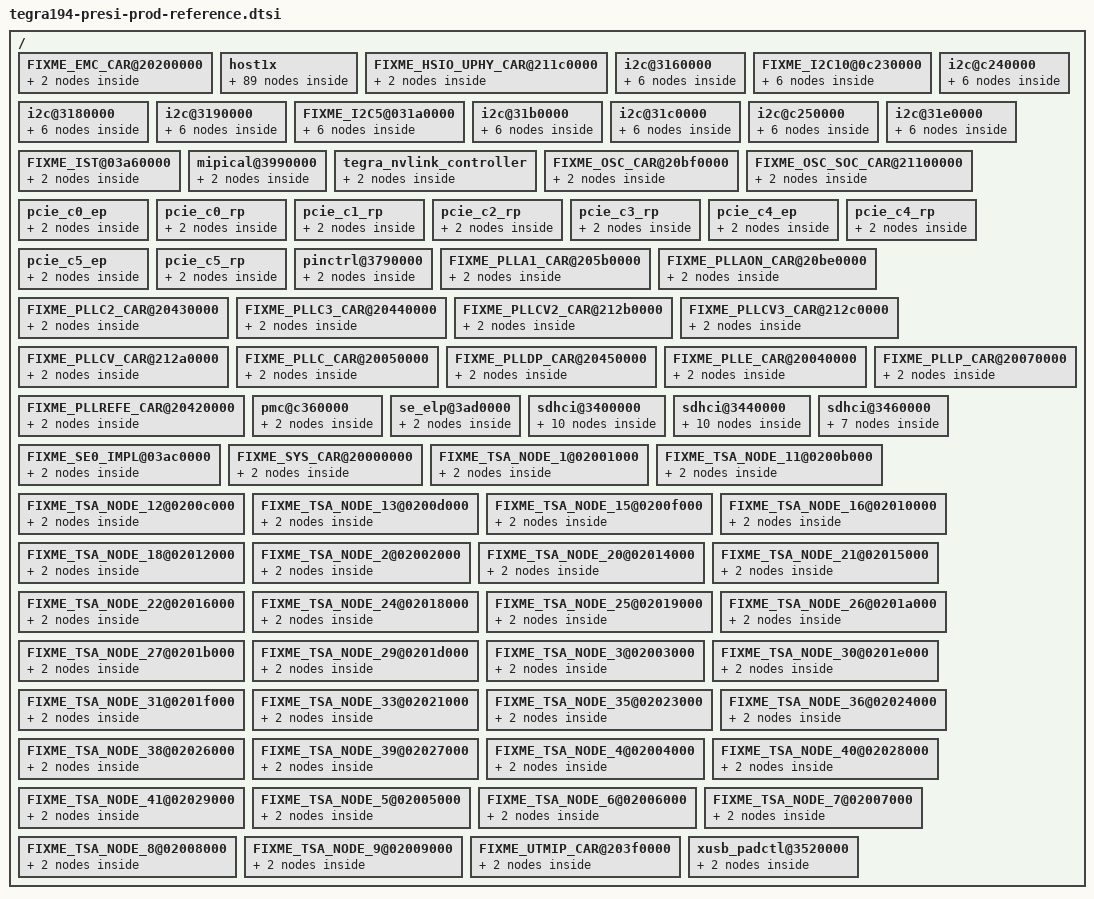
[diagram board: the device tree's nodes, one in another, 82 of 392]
/*
 * Copyright (c) 2017, NVIDIA CORPORATION.  All rights reserved.
 *
 * This program is free software; you can redistribute it and/or modify
 * it under the terms of the GNU General Public License as published by
 * the Free Software Foundation; version 2 of the License.
 *
 * This program is distributed in the hope that it will be useful, but WITHOUT
 * ANY WARRANTY; without even the implied warranty of MERCHANTABILITY or
 * FITNESS FOR A PARTICULAR PURPOSE.  See the GNU General Public License for
 * more details.
 *
 * You should have received a copy of the GNU General Public License along
 * with this program; if not, write to the Free Software Foundation, Inc.,
 * 51 Franklin Street, Fifth Floor, Boston, MA  02110-1301, USA.
 *
 */
/*
* tegra194-soc-prod.dtsi: soc specific Prod configuration.
* Generation date: 2017-12-11 11:48
* PLEASE DO NOT EDIT THIS FILE MANUALLY
* This file is autogenerated using the script gen_prod_dtsi.py V1.3
* NOTE: Do not use file as is. Copy the relevant section to existing file in tree.
* NOTE: FIXME nodes indicate nodes corresponding to Golden Register were not found in input DTB.
*       Please check if DTB has the nodes enabled and register address in GR DB is valid.
*/

/ {
	FIXME_EMC_CAR@20200000 {
		prod-settings {
			#prod-cells = <4>;
			prod {
				prod = <
					0 0x00003000 0x00108000 0x00008000>;            //CLK_RST_CONTROLLER_CLK_SOURCE_EMC_0
			};
		};
	};

	host1x {
		prod-settings {
			#prod-cells = <4>;
			prod {
				prod = <
					1 0x000022e4 0x0000ffff 0x00000808>;            //HOST1X_THOST_COMMON_CDMA_ASM_TIMEOUT_0
			};
		};

		se@15810000 {
			prod-settings {
				#prod-cells = <4>;
				prod {
					prod = <
						0 0x00000018 0x00020002 0x00000000>;            //SE1_SE_SECURITY_0
				};
			};
		};

		se@15820000 {
			prod-settings {
				#prod-cells = <4>;
				prod {
					prod = <
						0 0x00000018 0x00020002 0x00000000>;            //SE2_SE_SECURITY_0
				};
			};
		};

		se@15830000 {
			prod-settings {
				#prod-cells = <4>;
				prod {
					prod = <
						0 0x00000018 0x00020002 0x00000000>;            //SE3_SE_SECURITY_0
				};
			};
		};

		se@15840000 {
			prod-settings {
				#prod-cells = <4>;
				prod {
					prod = <
						0 0x00000018 0x00020002 0x00000000>;            //SE4_SE_SECURITY_0
				};
			};
		};

		sor {
			prod-settings {
				#prod-cells = <4>;
				prod_list_hdmi_soc = "prod_c_hdmi_0m_54m","prod_c_hdmi_54m_111m","prod_c_hdmi_111m_223m","prod_c_hdmi_223m_300m","prod_c_hdmi_300m_600m";
				prod_c_dp {
					prod = <
						0 0x000005a4 0x0f000000 0x05000000              //SOR_NV_PDISP_SOR_PLL0_0
						0 0x000005a8 0x03000100 0x00000100              //SOR_NV_PDISP_SOR_PLL1_0
						0 0x000005ac 0x02000000 0x02000000              //SOR_NV_PDISP_SOR_PLL2_0
						0 0x000005e4 0x00003b80 0x00001a00>;            //SOR_NV_PDISP_SOR_PLL5_0
				};
				prod_c_hbr {
					prod = <
						0 0x000005a8 0x00f00000 0x00300000>;            //SOR_NV_PDISP_SOR_PLL1_0
				};
				prod_c_hbr2 {
					prod = <
						0 0x000005a8 0x00f00000 0x00400000>;            //SOR_NV_PDISP_SOR_PLL1_0
				};
				prod_c_hbr3 {
					prod = <
						0 0x000005a8 0x00f00000 0x00400000>;            //SOR_NV_PDISP_SOR_PLL1_0
				};
				prod_c_hdmi_0m_54m {
					prod = <
						0 0x00000138 0xffffffff 0x333a3a3a              //SOR_NV_PDISP_SOR_LANE_DRIVE_CURRENT0_0
						0 0x00000148 0xffffffff 0x00000000              //SOR_NV_PDISP_SOR_LANE_PREEMPHASIS0_0
						0 0x000005e4 0x00003b80 0x00002a00>;            //SOR_NV_PDISP_SOR_PLL5_0
				};
				prod_c_hdmi_54m_111m {
					prod = <
						0 0x00000138 0xffffffff 0x333a3a3a              //SOR_NV_PDISP_SOR_LANE_DRIVE_CURRENT0_0
						0 0x00000148 0xffffffff 0x00000000              //SOR_NV_PDISP_SOR_LANE_PREEMPHASIS0_0
						0 0x000005e4 0x00003b80 0x00002200>;            //SOR_NV_PDISP_SOR_PLL5_0
				};
				prod_c_hdmi_111m_223m {
					prod = <
						0 0x00000138 0xffffffff 0x373a3a3a              //SOR_NV_PDISP_SOR_LANE_DRIVE_CURRENT0_0
						0 0x00000148 0xffffffff 0x00000000              //SOR_NV_PDISP_SOR_LANE_PREEMPHASIS0_0
						0 0x000005e4 0x00003b80 0x00001a00>;            //SOR_NV_PDISP_SOR_PLL5_0
				};
				prod_c_hdmi_223m_300m {
					prod = <
						0 0x00000138 0xffffffff 0x333d3d3d              //SOR_NV_PDISP_SOR_LANE_DRIVE_CURRENT0_0
						0 0x00000148 0xffffffff 0x00000000              //SOR_NV_PDISP_SOR_LANE_PREEMPHASIS0_0
						0 0x000005e4 0x00003b80 0x00001a00>;            //SOR_NV_PDISP_SOR_PLL5_0
				};
				prod_c_hdmi_300m_600m {
					prod = <
						0 0x00000138 0xffffffff 0x333d3d3d              //SOR_NV_PDISP_SOR_LANE_DRIVE_CURRENT0_0
						0 0x00000148 0xffffffff 0x00000000              //SOR_NV_PDISP_SOR_LANE_PREEMPHASIS0_0
						0 0x000005e4 0x00003b80 0x00001a00>;            //SOR_NV_PDISP_SOR_PLL5_0
				};
				prod_c_rbr {
					prod = <
						0 0x000005a8 0x00f00000 0x00300000>;            //SOR_NV_PDISP_SOR_PLL1_0
				};
			};
		};

		sor1 {
			prod-settings {
				#prod-cells = <4>;
				prod_list_hdmi_soc = "prod_c_hdmi_0m_54m","prod_c_hdmi_54m_111m","prod_c_hdmi_111m_223m","prod_c_hdmi_223m_300m","prod_c_hdmi_300m_600m";
				prod_c_dp {
					prod = <
						0 0x000005a4 0x0f000000 0x05000000              //SOR_NV_PDISP_SOR_PLL0_0
						0 0x000005a8 0x03000100 0x00000100              //SOR_NV_PDISP_SOR_PLL1_0
						0 0x000005ac 0x02000000 0x02000000              //SOR_NV_PDISP_SOR_PLL2_0
						0 0x000005e4 0x00003b80 0x00001a00>;            //SOR_NV_PDISP_SOR_PLL5_0
				};
				prod_c_hbr {
					prod = <
						0 0x000005a8 0x00f00000 0x00300000>;            //SOR_NV_PDISP_SOR_PLL1_0
				};
				prod_c_hbr2 {
					prod = <
						0 0x000005a8 0x00f00000 0x00400000>;            //SOR_NV_PDISP_SOR_PLL1_0
				};
				prod_c_hbr3 {
					prod = <
						0 0x000005a8 0x00f00000 0x00400000>;            //SOR_NV_PDISP_SOR_PLL1_0
				};
				prod_c_hdmi_0m_54m {
					prod = <
						0 0x00000138 0xffffffff 0x333a3a3a              //SOR_NV_PDISP_SOR_LANE_DRIVE_CURRENT0_0
						0 0x00000148 0xffffffff 0x00000000              //SOR_NV_PDISP_SOR_LANE_PREEMPHASIS0_0
						0 0x000005e4 0x00003b80 0x00002a00>;            //SOR_NV_PDISP_SOR_PLL5_0
				};
				prod_c_hdmi_54m_111m {
					prod = <
						0 0x00000138 0xffffffff 0x333a3a3a              //SOR_NV_PDISP_SOR_LANE_DRIVE_CURRENT0_0
						0 0x00000148 0xffffffff 0x00000000              //SOR_NV_PDISP_SOR_LANE_PREEMPHASIS0_0
						0 0x000005e4 0x00003b80 0x00002200>;            //SOR_NV_PDISP_SOR_PLL5_0
				};
				prod_c_hdmi_111m_223m {
					prod = <
						0 0x00000138 0xffffffff 0x373a3a3a              //SOR_NV_PDISP_SOR_LANE_DRIVE_CURRENT0_0
						0 0x00000148 0xffffffff 0x00000000              //SOR_NV_PDISP_SOR_LANE_PREEMPHASIS0_0
						0 0x000005e4 0x00003b80 0x00001a00>;            //SOR_NV_PDISP_SOR_PLL5_0
				};
				prod_c_hdmi_223m_300m {
					prod = <
						0 0x00000138 0xffffffff 0x333d3d3d              //SOR_NV_PDISP_SOR_LANE_DRIVE_CURRENT0_0
						0 0x00000148 0xffffffff 0x00000000              //SOR_NV_PDISP_SOR_LANE_PREEMPHASIS0_0
						0 0x000005e4 0x00003b80 0x00001a00>;            //SOR_NV_PDISP_SOR_PLL5_0
				};
				prod_c_hdmi_300m_600m {
					prod = <
						0 0x00000138 0xffffffff 0x333d3d3d              //SOR_NV_PDISP_SOR_LANE_DRIVE_CURRENT0_0
						0 0x00000148 0xffffffff 0x00000000              //SOR_NV_PDISP_SOR_LANE_PREEMPHASIS0_0
						0 0x000005e4 0x00003b80 0x00001a00>;            //SOR_NV_PDISP_SOR_PLL5_0
				};
				prod_c_rbr {
					prod = <
						0 0x000005a8 0x00f00000 0x00300000>;            //SOR_NV_PDISP_SOR_PLL1_0
				};
			};
		};

		sor2 {
			prod-settings {
				#prod-cells = <4>;
				prod_list_hdmi_soc = "prod_c_hdmi_0m_54m","prod_c_hdmi_54m_111m","prod_c_hdmi_111m_223m","prod_c_hdmi_223m_300m","prod_c_hdmi_300m_600m";
				prod_c_dp {
					prod = <
						0 0x000005a4 0x0f000000 0x05000000              //SOR_NV_PDISP_SOR_PLL0_0
						0 0x000005a8 0x03000100 0x00000100              //SOR_NV_PDISP_SOR_PLL1_0
						0 0x000005ac 0x02000000 0x02000000              //SOR_NV_PDISP_SOR_PLL2_0
						0 0x000005e4 0x00003b80 0x00001a00>;            //SOR_NV_PDISP_SOR_PLL5_0
				};
				prod_c_hbr {
					prod = <
						0 0x000005a8 0x00f00000 0x00300000>;            //SOR_NV_PDISP_SOR_PLL1_0
				};
				prod_c_hbr2 {
					prod = <
						0 0x000005a8 0x00f00000 0x00400000>;            //SOR_NV_PDISP_SOR_PLL1_0
				};
				prod_c_hbr3 {
					prod = <
						0 0x000005a8 0x00f00000 0x00400000>;            //SOR_NV_PDISP_SOR_PLL1_0
				};
				prod_c_hdmi_0m_54m {
					prod = <
						0 0x00000138 0xffffffff 0x333a3a3a              //SOR_NV_PDISP_SOR_LANE_DRIVE_CURRENT0_0
						0 0x00000148 0xffffffff 0x00000000              //SOR_NV_PDISP_SOR_LANE_PREEMPHASIS0_0
						0 0x000005e4 0x00003b80 0x00002a00>;            //SOR_NV_PDISP_SOR_PLL5_0
				};
				prod_c_hdmi_54m_111m {
					prod = <
						0 0x00000138 0xffffffff 0x333a3a3a              //SOR_NV_PDISP_SOR_LANE_DRIVE_CURRENT0_0
						0 0x00000148 0xffffffff 0x00000000              //SOR_NV_PDISP_SOR_LANE_PREEMPHASIS0_0
						0 0x000005e4 0x00003b80 0x00002200>;            //SOR_NV_PDISP_SOR_PLL5_0
				};
				prod_c_hdmi_111m_223m {
					prod = <
						0 0x00000138 0xffffffff 0x373a3a3a              //SOR_NV_PDISP_SOR_LANE_DRIVE_CURRENT0_0
						0 0x00000148 0xffffffff 0x00000000              //SOR_NV_PDISP_SOR_LANE_PREEMPHASIS0_0
						0 0x000005e4 0x00003b80 0x00001a00>;            //SOR_NV_PDISP_SOR_PLL5_0
				};
				prod_c_hdmi_223m_300m {
					prod = <
						0 0x00000138 0xffffffff 0x333d3d3d              //SOR_NV_PDISP_SOR_LANE_DRIVE_CURRENT0_0
						0 0x00000148 0xffffffff 0x00000000              //SOR_NV_PDISP_SOR_LANE_PREEMPHASIS0_0
						0 0x000005e4 0x00003b80 0x00001a00>;            //SOR_NV_PDISP_SOR_PLL5_0
				};
				prod_c_hdmi_300m_600m {
					prod = <
						0 0x00000138 0xffffffff 0x333d3d3d              //SOR_NV_PDISP_SOR_LANE_DRIVE_CURRENT0_0
						0 0x00000148 0xffffffff 0x00000000              //SOR_NV_PDISP_SOR_LANE_PREEMPHASIS0_0
						0 0x000005e4 0x00003b80 0x00001a00>;            //SOR_NV_PDISP_SOR_PLL5_0
				};
				prod_c_rbr {
					prod = <
						0 0x000005a8 0x00f00000 0x00300000>;            //SOR_NV_PDISP_SOR_PLL1_0
				};
			};
		};

		sor3 {
			prod-settings {
				#prod-cells = <4>;
				prod_list_hdmi_soc = "prod_c_hdmi_0m_54m","prod_c_hdmi_54m_111m","prod_c_hdmi_111m_223m","prod_c_hdmi_223m_300m","prod_c_hdmi_300m_600m";
				prod_c_dp {
					prod = <
						0 0x000005a4 0x0f000000 0x05000000              //SOR_NV_PDISP_SOR_PLL0_0
						0 0x000005a8 0x03000100 0x00000100              //SOR_NV_PDISP_SOR_PLL1_0
						0 0x000005ac 0x02000000 0x02000000              //SOR_NV_PDISP_SOR_PLL2_0
						0 0x000005e4 0x00003b80 0x00001a00>;            //SOR_NV_PDISP_SOR_PLL5_0
				};
				prod_c_hbr {
					prod = <
						0 0x000005a8 0x00f00000 0x00300000>;            //SOR_NV_PDISP_SOR_PLL1_0
				};
				prod_c_hbr2 {
					prod = <
						0 0x000005a8 0x00f00000 0x00400000>;            //SOR_NV_PDISP_SOR_PLL1_0
				};
				prod_c_hbr3 {
					prod = <
						0 0x000005a8 0x00f00000 0x00400000>;            //SOR_NV_PDISP_SOR_PLL1_0
				};
				prod_c_hdmi_0m_54m {
					prod = <
						0 0x00000138 0xffffffff 0x333a3a3a              //SOR_NV_PDISP_SOR_LANE_DRIVE_CURRENT0_0
						0 0x00000148 0xffffffff 0x00000000              //SOR_NV_PDISP_SOR_LANE_PREEMPHASIS0_0
						0 0x000005e4 0x00003b80 0x00002a00>;            //SOR_NV_PDISP_SOR_PLL5_0
				};
				prod_c_hdmi_54m_111m {
					prod = <
						0 0x00000138 0xffffffff 0x333a3a3a              //SOR_NV_PDISP_SOR_LANE_DRIVE_CURRENT0_0
						0 0x00000148 0xffffffff 0x00000000              //SOR_NV_PDISP_SOR_LANE_PREEMPHASIS0_0
						0 0x000005e4 0x00003b80 0x00002200>;            //SOR_NV_PDISP_SOR_PLL5_0
				};
				prod_c_hdmi_111m_223m {
					prod = <
						0 0x00000138 0xffffffff 0x373a3a3a              //SOR_NV_PDISP_SOR_LANE_DRIVE_CURRENT0_0
						0 0x00000148 0xffffffff 0x00000000              //SOR_NV_PDISP_SOR_LANE_PREEMPHASIS0_0
						0 0x000005e4 0x00003b80 0x00001a00>;            //SOR_NV_PDISP_SOR_PLL5_0
				};
				prod_c_hdmi_223m_300m {
					prod = <
						0 0x00000138 0xffffffff 0x333d3d3d              //SOR_NV_PDISP_SOR_LANE_DRIVE_CURRENT0_0
						0 0x00000148 0xffffffff 0x00000000              //SOR_NV_PDISP_SOR_LANE_PREEMPHASIS0_0
						0 0x000005e4 0x00003b80 0x00001a00>;            //SOR_NV_PDISP_SOR_PLL5_0
				};
				prod_c_hdmi_300m_600m {
					prod = <
						0 0x00000138 0xffffffff 0x333d3d3d              //SOR_NV_PDISP_SOR_LANE_DRIVE_CURRENT0_0
						0 0x00000148 0xffffffff 0x00000000              //SOR_NV_PDISP_SOR_LANE_PREEMPHASIS0_0
						0 0x000005e4 0x00003b80 0x00001a00>;            //SOR_NV_PDISP_SOR_PLL5_0
				};
				prod_c_rbr {
					prod = <
						0 0x000005a8 0x00f00000 0x00300000>;            //SOR_NV_PDISP_SOR_PLL1_0
				};
			};
		};

		dpaux@155c0000 {
			prod-settings {
				#prod-cells = <4>;
				prod_c_dpaux_hdmi {
					status = "disabled";
				};
				prod_c_dpaux_dp {
					status = "disabled";
				};
			};
		};

		dpaux@155D0000 {
			prod-settings {
				#prod-cells = <4>;
				prod_c_dpaux_hdmi {
					status = "disabled";
				};
				prod_c_dpaux_dp {
					status = "disabled";
				};
			};
		};

		dpaux@155E0000 {
			prod-settings {
				#prod-cells = <4>;
				prod_c_dpaux_hdmi {
					status = "disabled";
				};
				prod_c_dpaux_dp {
					status = "disabled";
				};
			};
		};

		dpaux@155F0000 {
			prod-settings {
				#prod-cells = <4>;
				prod_c_dpaux_hdmi {
					status = "disabled";
				};
				prod_c_dpaux_dp {
					status = "disabled";
				};
			};
		};

		nvcsi@15a00000 {
			prod-settings {
				#prod-cells = <4>;
				prod {
					prod = <
						0 0x00011018 0x00070000 0x00040000              //NVCSI_PHY_0_NVCSI_CIL_PAD_CONFIG_0
						0 0x0001109c 0xe000e000 0xc000c000              //NVCSI_PHY_0_NVCSI_CIL_A_CPHY_CALIB_CTRL_0
						0 0x000110a8 0x0000fefe 0x00004c4c              //NVCSI_PHY_0_NVCSI_CIL_A_CPHY_EDGE_DELAY_CTRL_0
						0 0x00011128 0xe000e000 0xc000c000              //NVCSI_PHY_0_NVCSI_CIL_B_CPHY_CALIB_CTRL_0
						0 0x00011134 0x0000fefe 0x00004c4c              //NVCSI_PHY_0_NVCSI_CIL_B_CPHY_EDGE_DELAY_CTRL_0
						0 0x00021018 0x00070000 0x00040000              //NVCSI_PHY_1_NVCSI_CIL_PAD_CONFIG_0
						0 0x0002109c 0xe000e000 0xc000c000              //NVCSI_PHY_1_NVCSI_CIL_A_CPHY_CALIB_CTRL_0
						0 0x000210a8 0x0000fefe 0x00004c4c              //NVCSI_PHY_1_NVCSI_CIL_A_CPHY_EDGE_DELAY_CTRL_0
						0 0x00021128 0xe000e000 0xc000c000              //NVCSI_PHY_1_NVCSI_CIL_B_CPHY_CALIB_CTRL_0
						0 0x00021134 0x0000fefe 0x00004c4c              //NVCSI_PHY_1_NVCSI_CIL_B_CPHY_EDGE_DELAY_CTRL_0
						0 0x00031018 0x00070000 0x00040000              //NVCSI_PHY_2_NVCSI_CIL_PAD_CONFIG_0
						0 0x0003109c 0xe000e000 0xc000c000              //NVCSI_PHY_2_NVCSI_CIL_A_CPHY_CALIB_CTRL_0
						0 0x000310a8 0x0000fefe 0x00004c4c              //NVCSI_PHY_2_NVCSI_CIL_A_CPHY_EDGE_DELAY_CTRL_0
						0 0x00031128 0xe000e000 0xc000c000              //NVCSI_PHY_2_NVCSI_CIL_B_CPHY_CALIB_CTRL_0
						0 0x00031134 0x0000fefe 0x00004c4c              //NVCSI_PHY_2_NVCSI_CIL_B_CPHY_EDGE_DELAY_CTRL_0
						0 0x00041018 0x00070000 0x00040000              //NVCSI_PHY_3_NVCSI_CIL_PAD_CONFIG_0
						0 0x0004109c 0xe000e000 0xc000c000              //NVCSI_PHY_3_NVCSI_CIL_A_CPHY_CALIB_CTRL_0
						0 0x000410a8 0x0000fefe 0x00004c4c              //NVCSI_PHY_3_NVCSI_CIL_A_CPHY_EDGE_DELAY_CTRL_0
						0 0x00041128 0xe000e000 0xc000c000              //NVCSI_PHY_3_NVCSI_CIL_B_CPHY_CALIB_CTRL_0
						0 0x00041134 0x0000fefe 0x00004c4c>;            //NVCSI_PHY_3_NVCSI_CIL_B_CPHY_EDGE_DELAY_CTRL_0
				};
				prod_c_cphy_mode {
					prod = <
						0 0x00011030 0x007f7f7f 0x00444444              //NVCSI_PHY_0_NVCSI_CIL_A_DPHY_INADJ_CTRL_0
						0 0x000110bc 0x007f7f7f 0x00444444              //NVCSI_PHY_0_NVCSI_CIL_B_DPHY_INADJ_CTRL_0
						0 0x00021030 0x007f7f7f 0x00444444              //NVCSI_PHY_1_NVCSI_CIL_A_DPHY_INADJ_CTRL_0
						0 0x000210bc 0x007f7f7f 0x00444444              //NVCSI_PHY_1_NVCSI_CIL_B_DPHY_INADJ_CTRL_0
						0 0x00031030 0x007f7f7f 0x00444444              //NVCSI_PHY_2_NVCSI_CIL_A_DPHY_INADJ_CTRL_0
						0 0x000310bc 0x007f7f7f 0x00444444              //NVCSI_PHY_2_NVCSI_CIL_B_DPHY_INADJ_CTRL_0
						0 0x00041030 0x007f7f7f 0x00444444              //NVCSI_PHY_3_NVCSI_CIL_A_DPHY_INADJ_CTRL_0
						0 0x000410bc 0x007f7f7f 0x00444444>;            //NVCSI_PHY_3_NVCSI_CIL_B_DPHY_INADJ_CTRL_0
				};
				prod_c_dphy_mode {
					prod = <
						0 0x00011030 0x007f7f7f 0x00000000              //NVCSI_PHY_0_NVCSI_CIL_A_DPHY_INADJ_CTRL_0
						0 0x000110bc 0x007f7f7f 0x00000000              //NVCSI_PHY_0_NVCSI_CIL_B_DPHY_INADJ_CTRL_0
						0 0x00021030 0x007f7f7f 0x00000000              //NVCSI_PHY_1_NVCSI_CIL_A_DPHY_INADJ_CTRL_0
						0 0x000210bc 0x007f7f7f 0x00000000              //NVCSI_PHY_1_NVCSI_CIL_B_DPHY_INADJ_CTRL_0
						0 0x00031030 0x007f7f7f 0x00000000              //NVCSI_PHY_2_NVCSI_CIL_A_DPHY_INADJ_CTRL_0
						0 0x000310bc 0x007f7f7f 0x00000000              //NVCSI_PHY_2_NVCSI_CIL_B_DPHY_INADJ_CTRL_0
						0 0x00041030 0x007f7f7f 0x00000000              //NVCSI_PHY_3_NVCSI_CIL_A_DPHY_INADJ_CTRL_0
						0 0x000410bc 0x007f7f7f 0x00000000>;            //NVCSI_PHY_3_NVCSI_CIL_B_DPHY_INADJ_CTRL_0
				};
			};
		};

		pva0 {
			prod-settings {
				#prod-cells = <4>;
				prod {
					prod = <
						0 0x00073000 0x00000001 0x00000001              //PVA_CFG_INTR_ENABLE_0
						0 0x00200050 0x00000001 0x00000000              //PVA_PM_TCM_CG_BYP_0
						0 0x00030000 0x00000001 0x00000001              //PVA_PROC_CPUHALT_0
						0 0x0002804c 0x000000ff 0x000000ff>;            //PVA_SEC_LIC_INTR_ENABLE_0
				};
			};
		};

		pva1 {
			prod-settings {
				#prod-cells = <4>;
				prod {
					prod = <
						0 0x00073000 0x00000001 0x00000001              //PVA_CFG_INTR_ENABLE_0
						0 0x00200050 0x00000001 0x00000000              //PVA_PM_TCM_CG_BYP_0
						0 0x00030000 0x00000001 0x00000001              //PVA_PROC_CPUHALT_0
						0 0x0002804c 0x000000ff 0x000000ff>;            //PVA_SEC_LIC_INTR_ENABLE_0
				};
			};
		};
	};

	FIXME_HSIO_UPHY_CAR@211c0000 {
		prod-settings {
			#prod-cells = <4>;
			prod {
				prod = <
					0 0x00000000 0x01100005 0x01100004              //CLK_RST_CONTROLLER_HSIO_UPHY_PLL0_CFG0_0
					0 0x00000010 0x01122005 0x01120004              //CLK_RST_CONTROLLER_HSIO_UPHY_PLL1_CFG0_0
					0 0x00000020 0x01100005 0x01100004              //CLK_RST_CONTROLLER_HSIO_UPHY_PLL2_CFG0_0
					0 0x00000030 0x01122005 0x01120004>;            //CLK_RST_CONTROLLER_HSIO_UPHY_PLL3_CFG0_0
			};
		};
	};

	i2c@3160000 {
		prod-settings {
			#prod-cells = <4>;
			prod {
				prod = <
					0 0x0000009c 0x0000ffff 0x00000308              //I2C_I2C_HS_INTERFACE_TIMING_0_0
					0 0x000000d4 0x000000ff 0x00000000              //I2C_I2C_INTERFACE_TIMING_2_0
					0 0x000000d8 0x000000ff 0x00000000              //I2C_I2C_HS_INTERFACE_TIMING_2_0
					0 0x000000dc 0x0000ffff 0x00000001              //I2C_I2C_MSTR_DATA_CAPTURE_TIMING_0
					0 0x000000e0 0x0000ffff 0x00000002>;            //I2C_I2C_SLV_DATA_CAPTURE_TIMING_0
			};
			prod_c_fm {
				prod = <
					0 0x0000006c 0xffff0000 0x00580000              //I2C_I2C_CLK_DIVISOR_REGISTER_0
					0 0x00000094 0x0000ffff 0x00000101              //I2C_I2C_INTERFACE_TIMING_0_0
					0 0x00000098 0xffffffff 0x02020202>;            //I2C_I2C_INTERFACE_TIMING_1_0
			};
			prod_c_fmplus {
				prod = <
					0 0x0000006c 0xffff0000 0x00240000              //I2C_I2C_CLK_DIVISOR_REGISTER_0
					0 0x00000094 0x0000ffff 0x00000101              //I2C_I2C_INTERFACE_TIMING_0_0
					0 0x00000098 0xffffffff 0x02020202>;            //I2C_I2C_INTERFACE_TIMING_1_0
			};
			prod_c_hs {
				prod = <
					0 0x0000006c 0xffffffff 0x00580002              //I2C_I2C_CLK_DIVISOR_REGISTER_0
					0 0x00000094 0x0000ffff 0x00000101              //I2C_I2C_INTERFACE_TIMING_0_0
					0 0x00000098 0xffffffff 0x02020202              //I2C_I2C_INTERFACE_TIMING_1_0
					0 0x000000a0 0x00ffffff 0x00090909>;            //I2C_I2C_HS_INTERFACE_TIMING_1_0
			};
			prod_c_sm {
				prod = <
					0 0x0000006c 0xffff0000 0x004f0000              //I2C_I2C_CLK_DIVISOR_REGISTER_0
					0 0x00000094 0x0000ffff 0x00000708              //I2C_I2C_INTERFACE_TIMING_0_0
					0 0x00000098 0xffffffff 0x08080808>;            //I2C_I2C_INTERFACE_TIMING_1_0
			};
		};
	};

	FIXME_I2C10@0c230000 {
		prod-settings {
			#prod-cells = <4>;
			prod {
				prod = <
					0 0x0000009c 0x0000ffff 0x00000308              //I2C_I2C_HS_INTERFACE_TIMING_0_0
					0 0x000000d4 0x000000ff 0x00000000              //I2C_I2C_INTERFACE_TIMING_2_0
					0 0x000000d8 0x000000ff 0x00000000              //I2C_I2C_HS_INTERFACE_TIMING_2_0
					0 0x000000dc 0x0000ffff 0x00000001              //I2C_I2C_MSTR_DATA_CAPTURE_TIMING_0
					0 0x000000e0 0x0000ffff 0x00000002>;            //I2C_I2C_SLV_DATA_CAPTURE_TIMING_0
			};
			prod_c_fm {
				prod = <
					0 0x0000006c 0xffff0000 0x00580000              //I2C_I2C_CLK_DIVISOR_REGISTER_0
					0 0x00000094 0x0000ffff 0x00000101              //I2C_I2C_INTERFACE_TIMING_0_0
					0 0x00000098 0xffffffff 0x02020202>;            //I2C_I2C_INTERFACE_TIMING_1_0
			};
			prod_c_fmplus {
				prod = <
					0 0x0000006c 0xffff0000 0x00240000              //I2C_I2C_CLK_DIVISOR_REGISTER_0
					0 0x00000094 0x0000ffff 0x00000101              //I2C_I2C_INTERFACE_TIMING_0_0
					0 0x00000098 0xffffffff 0x02020202>;            //I2C_I2C_INTERFACE_TIMING_1_0
			};
			prod_c_hs {
				prod = <
					0 0x0000006c 0xffffffff 0x00580002              //I2C_I2C_CLK_DIVISOR_REGISTER_0
					0 0x00000094 0x0000ffff 0x00000101              //I2C_I2C_INTERFACE_TIMING_0_0
					0 0x00000098 0xffffffff 0x02020202              //I2C_I2C_INTERFACE_TIMING_1_0
					0 0x000000a0 0x00ffffff 0x00090909>;            //I2C_I2C_HS_INTERFACE_TIMING_1_0
			};
			prod_c_sm {
				prod = <
					0 0x0000006c 0xffff0000 0x004f0000              //I2C_I2C_CLK_DIVISOR_REGISTER_0
					0 0x00000094 0x0000ffff 0x00000708              //I2C_I2C_INTERFACE_TIMING_0_0
					0 0x00000098 0xffffffff 0x08080808>;            //I2C_I2C_INTERFACE_TIMING_1_0
			};
		};
	};

	i2c@c240000 {
		prod-settings {
			#prod-cells = <4>;
			prod {
				prod = <
					0 0x0000009c 0x0000ffff 0x00000308              //I2C_I2C_HS_INTERFACE_TIMING_0_0
					0 0x000000d4 0x000000ff 0x00000000              //I2C_I2C_INTERFACE_TIMING_2_0
					0 0x000000d8 0x000000ff 0x00000000              //I2C_I2C_HS_INTERFACE_TIMING_2_0
					0 0x000000dc 0x0000ffff 0x00000001              //I2C_I2C_MSTR_DATA_CAPTURE_TIMING_0
					0 0x000000e0 0x0000ffff 0x00000002>;            //I2C_I2C_SLV_DATA_CAPTURE_TIMING_0
			};
			prod_c_fm {
				prod = <
					0 0x0000006c 0xffff0000 0x00580000              //I2C_I2C_CLK_DIVISOR_REGISTER_0
					0 0x00000094 0x0000ffff 0x00000101              //I2C_I2C_INTERFACE_TIMING_0_0
					0 0x00000098 0xffffffff 0x02020202>;            //I2C_I2C_INTERFACE_TIMING_1_0
			};
			prod_c_fmplus {
				prod = <
					0 0x0000006c 0xffff0000 0x00240000              //I2C_I2C_CLK_DIVISOR_REGISTER_0
					0 0x00000094 0x0000ffff 0x00000101              //I2C_I2C_INTERFACE_TIMING_0_0
					0 0x00000098 0xffffffff 0x02020202>;            //I2C_I2C_INTERFACE_TIMING_1_0
			};
			prod_c_hs {
				prod = <
					0 0x0000006c 0xffffffff 0x00580002              //I2C_I2C_CLK_DIVISOR_REGISTER_0
					0 0x00000094 0x0000ffff 0x00000101              //I2C_I2C_INTERFACE_TIMING_0_0
					0 0x00000098 0xffffffff 0x02020202              //I2C_I2C_INTERFACE_TIMING_1_0
					0 0x000000a0 0x00ffffff 0x00090909>;            //I2C_I2C_HS_INTERFACE_TIMING_1_0
			};
			prod_c_sm {
				prod = <
					0 0x0000006c 0xffff0000 0x004f0000              //I2C_I2C_CLK_DIVISOR_REGISTER_0
					0 0x00000094 0x0000ffff 0x00000708              //I2C_I2C_INTERFACE_TIMING_0_0
					0 0x00000098 0xffffffff 0x08080808>;            //I2C_I2C_INTERFACE_TIMING_1_0
			};
		};
	};

	i2c@3180000 {
		prod-settings {
			#prod-cells = <4>;
			prod {
				prod = <
					0 0x0000009c 0x0000ffff 0x00000308              //I2C_I2C_HS_INTERFACE_TIMING_0_0
					0 0x000000d4 0x000000ff 0x00000000              //I2C_I2C_INTERFACE_TIMING_2_0
					0 0x000000d8 0x000000ff 0x00000000              //I2C_I2C_HS_INTERFACE_TIMING_2_0
					0 0x000000dc 0x0000ffff 0x00000001              //I2C_I2C_MSTR_DATA_CAPTURE_TIMING_0
					0 0x000000e0 0x0000ffff 0x00000002>;            //I2C_I2C_SLV_DATA_CAPTURE_TIMING_0
			};
			prod_c_fm {
				prod = <
					0 0x0000006c 0xffff0000 0x00580000              //I2C_I2C_CLK_DIVISOR_REGISTER_0
					0 0x00000094 0x0000ffff 0x00000101              //I2C_I2C_INTERFACE_TIMING_0_0
					0 0x00000098 0xffffffff 0x02020202>;            //I2C_I2C_INTERFACE_TIMING_1_0
			};
			prod_c_fmplus {
				prod = <
					0 0x0000006c 0xffff0000 0x00240000              //I2C_I2C_CLK_DIVISOR_REGISTER_0
					0 0x00000094 0x0000ffff 0x00000101              //I2C_I2C_INTERFACE_TIMING_0_0
					0 0x00000098 0xffffffff 0x02020202>;            //I2C_I2C_INTERFACE_TIMING_1_0
			};
			prod_c_hs {
				prod = <
					0 0x0000006c 0xffffffff 0x00580002              //I2C_I2C_CLK_DIVISOR_REGISTER_0
					0 0x00000094 0x0000ffff 0x00000101              //I2C_I2C_INTERFACE_TIMING_0_0
					0 0x00000098 0xffffffff 0x02020202              //I2C_I2C_INTERFACE_TIMING_1_0
					0 0x000000a0 0x00ffffff 0x00090909>;            //I2C_I2C_HS_INTERFACE_TIMING_1_0
			};
			prod_c_sm {
				prod = <
					0 0x0000006c 0xffff0000 0x004f0000              //I2C_I2C_CLK_DIVISOR_REGISTER_0
					0 0x00000094 0x0000ffff 0x00000708              //I2C_I2C_INTERFACE_TIMING_0_0
					0 0x00000098 0xffffffff 0x08080808>;            //I2C_I2C_INTERFACE_TIMING_1_0
			};
		};
	};

	i2c@3190000 {
		prod-settings {
			#prod-cells = <4>;
			prod {
				prod = <
					0 0x0000009c 0x0000ffff 0x00000308              //I2C_I2C_HS_INTERFACE_TIMING_0_0
					0 0x000000d4 0x000000ff 0x00000000              //I2C_I2C_INTERFACE_TIMING_2_0
					0 0x000000d8 0x000000ff 0x00000000              //I2C_I2C_HS_INTERFACE_TIMING_2_0
					0 0x000000dc 0x0000ffff 0x00000001              //I2C_I2C_MSTR_DATA_CAPTURE_TIMING_0
					0 0x000000e0 0x0000ffff 0x00000002>;            //I2C_I2C_SLV_DATA_CAPTURE_TIMING_0
			};
			prod_c_fm {
				prod = <
					0 0x0000006c 0xffff0000 0x00580000              //I2C_I2C_CLK_DIVISOR_REGISTER_0
					0 0x00000094 0x0000ffff 0x00000101              //I2C_I2C_INTERFACE_TIMING_0_0
					0 0x00000098 0xffffffff 0x02020202>;            //I2C_I2C_INTERFACE_TIMING_1_0
			};
			prod_c_fmplus {
				prod = <
					0 0x0000006c 0xffff0000 0x00240000              //I2C_I2C_CLK_DIVISOR_REGISTER_0
					0 0x00000094 0x0000ffff 0x00000101              //I2C_I2C_INTERFACE_TIMING_0_0
					0 0x00000098 0xffffffff 0x02020202>;            //I2C_I2C_INTERFACE_TIMING_1_0
			};
			prod_c_hs {
				prod = <
					0 0x0000006c 0xffffffff 0x00580002              //I2C_I2C_CLK_DIVISOR_REGISTER_0
					0 0x00000094 0x0000ffff 0x00000101              //I2C_I2C_INTERFACE_TIMING_0_0
					0 0x00000098 0xffffffff 0x02020202              //I2C_I2C_INTERFACE_TIMING_1_0
					0 0x000000a0 0x00ffffff 0x00090909>;            //I2C_I2C_HS_INTERFACE_TIMING_1_0
			};
			prod_c_sm {
				prod = <
					0 0x0000006c 0xffff0000 0x004f0000              //I2C_I2C_CLK_DIVISOR_REGISTER_0
					0 0x00000094 0x0000ffff 0x00000708              //I2C_I2C_INTERFACE_TIMING_0_0
					0 0x00000098 0xffffffff 0x08080808>;            //I2C_I2C_INTERFACE_TIMING_1_0
			};
		};
	};

	FIXME_I2C5@031a0000 {
		prod-settings {
			#prod-cells = <4>;
			prod {
				prod = <
					0 0x0000009c 0x0000ffff 0x00000308              //I2C_I2C_HS_INTERFACE_TIMING_0_0
					0 0x000000d4 0x000000ff 0x00000000              //I2C_I2C_INTERFACE_TIMING_2_0
					0 0x000000d8 0x000000ff 0x00000000              //I2C_I2C_HS_INTERFACE_TIMING_2_0
					0 0x000000dc 0x0000ffff 0x00000001              //I2C_I2C_MSTR_DATA_CAPTURE_TIMING_0
					0 0x000000e0 0x0000ffff 0x00000002>;            //I2C_I2C_SLV_DATA_CAPTURE_TIMING_0
			};
			prod_c_fm {
				prod = <
					0 0x0000006c 0xffff0000 0x00580000              //I2C_I2C_CLK_DIVISOR_REGISTER_0
					0 0x00000094 0x0000ffff 0x00000101              //I2C_I2C_INTERFACE_TIMING_0_0
					0 0x00000098 0xffffffff 0x02020202>;            //I2C_I2C_INTERFACE_TIMING_1_0
			};
			prod_c_fmplus {
				prod = <
					0 0x0000006c 0xffff0000 0x00240000              //I2C_I2C_CLK_DIVISOR_REGISTER_0
					0 0x00000094 0x0000ffff 0x00000101              //I2C_I2C_INTERFACE_TIMING_0_0
					0 0x00000098 0xffffffff 0x02020202>;            //I2C_I2C_INTERFACE_TIMING_1_0
			};
			prod_c_hs {
				prod = <
					0 0x0000006c 0xffffffff 0x00580002              //I2C_I2C_CLK_DIVISOR_REGISTER_0
					0 0x00000094 0x0000ffff 0x00000101              //I2C_I2C_INTERFACE_TIMING_0_0
					0 0x00000098 0xffffffff 0x02020202              //I2C_I2C_INTERFACE_TIMING_1_0
					0 0x000000a0 0x00ffffff 0x00090909>;            //I2C_I2C_HS_INTERFACE_TIMING_1_0
			};
			prod_c_sm {
				prod = <
					0 0x0000006c 0xffff0000 0x004f0000              //I2C_I2C_CLK_DIVISOR_REGISTER_0
					0 0x00000094 0x0000ffff 0x00000708              //I2C_I2C_INTERFACE_TIMING_0_0
					0 0x00000098 0xffffffff 0x08080808>;            //I2C_I2C_INTERFACE_TIMING_1_0
			};
		};
	};

	i2c@31b0000 {
		prod-settings {
			#prod-cells = <4>;
			prod {
				prod = <
					0 0x0000009c 0x0000ffff 0x00000308              //I2C_I2C_HS_INTERFACE_TIMING_0_0
					0 0x000000d4 0x000000ff 0x00000000              //I2C_I2C_INTERFACE_TIMING_2_0
					0 0x000000d8 0x000000ff 0x00000000              //I2C_I2C_HS_INTERFACE_TIMING_2_0
					0 0x000000dc 0x0000ffff 0x00000001              //I2C_I2C_MSTR_DATA_CAPTURE_TIMING_0
					0 0x000000e0 0x0000ffff 0x00000002>;            //I2C_I2C_SLV_DATA_CAPTURE_TIMING_0
			};
			prod_c_fm {
				prod = <
					0 0x0000006c 0xffff0000 0x00580000              //I2C_I2C_CLK_DIVISOR_REGISTER_0
					0 0x00000094 0x0000ffff 0x00000101              //I2C_I2C_INTERFACE_TIMING_0_0
					0 0x00000098 0xffffffff 0x02020202>;            //I2C_I2C_INTERFACE_TIMING_1_0
			};
			prod_c_fmplus {
				prod = <
					0 0x0000006c 0xffff0000 0x00240000              //I2C_I2C_CLK_DIVISOR_REGISTER_0
					0 0x00000094 0x0000ffff 0x00000101              //I2C_I2C_INTERFACE_TIMING_0_0
					0 0x00000098 0xffffffff 0x02020202>;            //I2C_I2C_INTERFACE_TIMING_1_0
			};
			prod_c_hs {
				prod = <
					0 0x0000006c 0xffffffff 0x00580002              //I2C_I2C_CLK_DIVISOR_REGISTER_0
					0 0x00000094 0x0000ffff 0x00000101              //I2C_I2C_INTERFACE_TIMING_0_0
					0 0x00000098 0xffffffff 0x02020202              //I2C_I2C_INTERFACE_TIMING_1_0
					0 0x000000a0 0x00ffffff 0x00090909>;            //I2C_I2C_HS_INTERFACE_TIMING_1_0
			};
			prod_c_sm {
				prod = <
					0 0x0000006c 0xffff0000 0x004f0000              //I2C_I2C_CLK_DIVISOR_REGISTER_0
					0 0x00000094 0x0000ffff 0x00000708              //I2C_I2C_INTERFACE_TIMING_0_0
					0 0x00000098 0xffffffff 0x08080808>;            //I2C_I2C_INTERFACE_TIMING_1_0
			};
		};
	};

	i2c@31c0000 {
		prod-settings {
			#prod-cells = <4>;
			prod {
				prod = <
					0 0x0000009c 0x0000ffff 0x00000308              //I2C_I2C_HS_INTERFACE_TIMING_0_0
					0 0x000000d4 0x000000ff 0x00000000              //I2C_I2C_INTERFACE_TIMING_2_0
					0 0x000000d8 0x000000ff 0x00000000              //I2C_I2C_HS_INTERFACE_TIMING_2_0
					0 0x000000dc 0x0000ffff 0x00000001              //I2C_I2C_MSTR_DATA_CAPTURE_TIMING_0
					0 0x000000e0 0x0000ffff 0x00000002>;            //I2C_I2C_SLV_DATA_CAPTURE_TIMING_0
			};
			prod_c_fm {
				prod = <
					0 0x0000006c 0xffff0000 0x00580000              //I2C_I2C_CLK_DIVISOR_REGISTER_0
					0 0x00000094 0x0000ffff 0x00000101              //I2C_I2C_INTERFACE_TIMING_0_0
					0 0x00000098 0xffffffff 0x02020202>;            //I2C_I2C_INTERFACE_TIMING_1_0
			};
			prod_c_fmplus {
				prod = <
					0 0x0000006c 0xffff0000 0x00240000              //I2C_I2C_CLK_DIVISOR_REGISTER_0
					0 0x00000094 0x0000ffff 0x00000101              //I2C_I2C_INTERFACE_TIMING_0_0
					0 0x00000098 0xffffffff 0x02020202>;            //I2C_I2C_INTERFACE_TIMING_1_0
			};
			prod_c_hs {
				prod = <
					0 0x0000006c 0xffffffff 0x00580002              //I2C_I2C_CLK_DIVISOR_REGISTER_0
					0 0x00000094 0x0000ffff 0x00000101              //I2C_I2C_INTERFACE_TIMING_0_0
					0 0x00000098 0xffffffff 0x02020202              //I2C_I2C_INTERFACE_TIMING_1_0
					0 0x000000a0 0x00ffffff 0x00090909>;            //I2C_I2C_HS_INTERFACE_TIMING_1_0
			};
			prod_c_sm {
				prod = <
					0 0x0000006c 0xffff0000 0x004f0000              //I2C_I2C_CLK_DIVISOR_REGISTER_0
					0 0x00000094 0x0000ffff 0x00000708              //I2C_I2C_INTERFACE_TIMING_0_0
					0 0x00000098 0xffffffff 0x08080808>;            //I2C_I2C_INTERFACE_TIMING_1_0
			};
		};
	};

	i2c@c250000 {
		prod-settings {
			#prod-cells = <4>;
			prod {
				prod = <
					0 0x0000009c 0x0000ffff 0x00000308              //I2C_I2C_HS_INTERFACE_TIMING_0_0
					0 0x000000d4 0x000000ff 0x00000000              //I2C_I2C_INTERFACE_TIMING_2_0
					0 0x000000d8 0x000000ff 0x00000000              //I2C_I2C_HS_INTERFACE_TIMING_2_0
					0 0x000000dc 0x0000ffff 0x00000001              //I2C_I2C_MSTR_DATA_CAPTURE_TIMING_0
					0 0x000000e0 0x0000ffff 0x00000002>;            //I2C_I2C_SLV_DATA_CAPTURE_TIMING_0
			};
			prod_c_fm {
				prod = <
					0 0x0000006c 0xffff0000 0x00580000              //I2C_I2C_CLK_DIVISOR_REGISTER_0
					0 0x00000094 0x0000ffff 0x00000101              //I2C_I2C_INTERFACE_TIMING_0_0
					0 0x00000098 0xffffffff 0x02020202>;            //I2C_I2C_INTERFACE_TIMING_1_0
			};
			prod_c_fmplus {
				prod = <
					0 0x0000006c 0xffff0000 0x00240000              //I2C_I2C_CLK_DIVISOR_REGISTER_0
					0 0x00000094 0x0000ffff 0x00000101              //I2C_I2C_INTERFACE_TIMING_0_0
					0 0x00000098 0xffffffff 0x02020202>;            //I2C_I2C_INTERFACE_TIMING_1_0
			};
			prod_c_hs {
				prod = <
					0 0x0000006c 0xffffffff 0x00580002              //I2C_I2C_CLK_DIVISOR_REGISTER_0
					0 0x00000094 0x0000ffff 0x00000101              //I2C_I2C_INTERFACE_TIMING_0_0
					0 0x00000098 0xffffffff 0x02020202              //I2C_I2C_INTERFACE_TIMING_1_0
					0 0x000000a0 0x00ffffff 0x00090909>;            //I2C_I2C_HS_INTERFACE_TIMING_1_0
			};
			prod_c_sm {
				prod = <
					0 0x0000006c 0xffff0000 0x004f0000              //I2C_I2C_CLK_DIVISOR_REGISTER_0
					0 0x00000094 0x0000ffff 0x00000708              //I2C_I2C_INTERFACE_TIMING_0_0
					0 0x00000098 0xffffffff 0x08080808>;            //I2C_I2C_INTERFACE_TIMING_1_0
			};
		};
	};

	i2c@31e0000 {
		prod-settings {
			#prod-cells = <4>;
			prod {
				prod = <
					0 0x0000009c 0x0000ffff 0x00000308              //I2C_I2C_HS_INTERFACE_TIMING_0_0
					0 0x000000d4 0x000000ff 0x00000000              //I2C_I2C_INTERFACE_TIMING_2_0
					0 0x000000d8 0x000000ff 0x00000000              //I2C_I2C_HS_INTERFACE_TIMING_2_0
					0 0x000000dc 0x0000ffff 0x00000001              //I2C_I2C_MSTR_DATA_CAPTURE_TIMING_0
					0 0x000000e0 0x0000ffff 0x00000002>;            //I2C_I2C_SLV_DATA_CAPTURE_TIMING_0
			};
			prod_c_fm {
				prod = <
					0 0x0000006c 0xffff0000 0x00580000              //I2C_I2C_CLK_DIVISOR_REGISTER_0
					0 0x00000094 0x0000ffff 0x00000101              //I2C_I2C_INTERFACE_TIMING_0_0
					0 0x00000098 0xffffffff 0x02020202>;            //I2C_I2C_INTERFACE_TIMING_1_0
			};
			prod_c_fmplus {
				prod = <
					0 0x0000006c 0xffff0000 0x00240000              //I2C_I2C_CLK_DIVISOR_REGISTER_0
					0 0x00000094 0x0000ffff 0x00000101              //I2C_I2C_INTERFACE_TIMING_0_0
					0 0x00000098 0xffffffff 0x02020202>;            //I2C_I2C_INTERFACE_TIMING_1_0
			};
			prod_c_hs {
				prod = <
					0 0x0000006c 0xffffffff 0x00580002              //I2C_I2C_CLK_DIVISOR_REGISTER_0
					0 0x00000094 0x0000ffff 0x00000101              //I2C_I2C_INTERFACE_TIMING_0_0
					0 0x00000098 0xffffffff 0x02020202              //I2C_I2C_INTERFACE_TIMING_1_0
					0 0x000000a0 0x00ffffff 0x00090909>;            //I2C_I2C_HS_INTERFACE_TIMING_1_0
			};
			prod_c_sm {
				prod = <
					0 0x0000006c 0xffff0000 0x004f0000              //I2C_I2C_CLK_DIVISOR_REGISTER_0
					0 0x00000094 0x0000ffff 0x00000708              //I2C_I2C_INTERFACE_TIMING_0_0
					0 0x00000098 0xffffffff 0x08080808>;            //I2C_I2C_INTERFACE_TIMING_1_0
			};
		};
	};

	FIXME_IST@03a60000 {
		prod-settings {
			#prod-cells = <4>;
			prod {
				prod = <
					0 0x00000000 0x00000001 0x00000000              //IST_IST_TRIGGER_0
					0 0x00000004 0xffffffff 0x00000000              //IST_EMMC_START_ADDRESS_0
					0 0x00000008 0x00000001 0x00000000              //IST_DGPU_IST_0
					0 0x0000000c 0x00000001 0x00000000              //IST_EMMC_CARD_SETTINGS_0
					0 0x00000010 0xffffffff 0x00000000              //IST_INTERRUPT_MASK_0_0
					0 0x00000014 0xffffffff 0x00000000              //IST_INTERRUPT_MASK_1_0
					0 0x00000018 0x0000ffff 0x00000000              //IST_INTERRUPT_MASK_2_0
					0 0x0000001c 0xffffffff 0x0057e400              //IST_GLOBAL_SHUTDOWN_TIMEOUT_0
					0 0x00000020 0xffffffff 0x01312d00              //IST_JTAGCTRL_TIMEOUT_0
					0 0x00000024 0xffffffff 0x01312d00              //IST_EMMCCTRL_TIMEOUT_0
					0 0x00000028 0xffffffff 0x01312d00              //IST_LBISTTOP_TIMEOUT_0
					0 0x0000002c 0xffffffff 0x06146580              //IST_DGPULINK_TRAIN_TIMEOUT_0
					0 0x00000030 0xffffffff 0x01312d00              //IST_DGPULINK_POSTTRAIN_TIMEOUT_0
					0 0x00000034 0x00000007 0x00000000              //IST_DEBUG_CAPTURE_0
					0 0x00000038 0x00000001 0x00000000              //IST_LINK_CONTROLS_0
					0 0x0000003c 0xffffffff 0x00000000              //IST_RAM_CTRL_START_DWORD_0
					0 0x00000040 0xffffffff 0x00000000              //IST_RAM_CTRL_NO_DWORDS_0
					0 0x00000044 0x00000007 0x00000000              //IST_RAM_CTRL_EN_0
					0 0x00000048 0xffffffff 0x00000000              //IST_RAM_LOAD_DATA_0
					0 0x0000004c 0xffffffff 0x00000000              //IST_RAM_READ_DATA_0
					0 0x00000050 0x00000007 0x00000000              //IST_RAM_STATUS_0
					0 0x00000054 0xffffffff 0x00000000              //IST_RAM_TARGET_DWORD_0
					0 0x00000058 0x0000ffff 0x00001770              //IST_LINK_SHUTDOWN_TIMEOUT_0
					0 0x0000005c 0x0000ffff 0x00001770              //IST_GPU_CLK_SHUTDOWN_TIMEOUT_0
					0 0x00000060 0x00000001 0x00000000>;            //IST_ALLOW_EMMC_DATA_0
			};
		};
	};

	mipical@3990000 {
		prod-settings {
			#prod-cells = <4>;
			prod {
				prod = <
					0 0x00000044 0x00001f00 0x00000200              //MIPI_CAL_DSIA_MIPI_CAL_CONFIG_0
					0 0x00000048 0x00001f00 0x00000200              //MIPI_CAL_DSIB_MIPI_CAL_CONFIG_0
					0 0x0000004c 0x00001f00 0x00000200              //MIPI_CAL_DSIC_MIPI_CAL_CONFIG_0
					0 0x00000050 0x00001f00 0x00000200              //MIPI_CAL_DSID_MIPI_CAL_CONFIG_0
					0 0x0000006c 0x000f00f4 0x00010010              //MIPI_CAL_MIPI_BIAS_PAD_CFG2_0
					0 0x00000070 0x0000001f 0x00000002              //MIPI_CAL_DSIA_MIPI_CAL_CONFIG_2_0
					0 0x00000074 0x0000001f 0x00000002              //MIPI_CAL_DSIB_MIPI_CAL_CONFIG_2_0
					0 0x0000007c 0x0000001f 0x00000002              //MIPI_CAL_DSIC_MIPI_CAL_CONFIG_2_0
					0 0x00000080 0x0000001f 0x00000002>;            //MIPI_CAL_DSID_MIPI_CAL_CONFIG_2_0
			};
		};
	};

	tegra_nvlink_controller {
		prod-settings {
			#prod-cells = <4>;
			prod {
				prod = <
					6 0x00000038 0x00000001 0x00000001              //MSSNVLINK_LINK_CONTROL_0
					6 0x00000054 0x003fffff 0x00000000              //MSSNVLINK_MSSNVLINK_REGULAR_INTMASK_0
					6 0x00000058 0x003fffff 0x00000000              //MSSNVLINK_MSSNVLINK_CRITICAL_INTMASK_0
					7 0x00000038 0x00000001 0x00000001              //MSSNVLINK_LINK_CONTROL_0
					7 0x00000054 0x003fffff 0x00000000              //MSSNVLINK_MSSNVLINK_REGULAR_INTMASK_0
					7 0x00000058 0x003fffff 0x00000000              //MSSNVLINK_MSSNVLINK_CRITICAL_INTMASK_0
					8 0x00000038 0x00000001 0x00000001              //MSSNVLINK_LINK_CONTROL_0
					8 0x00000054 0x003fffff 0x00000000              //MSSNVLINK_MSSNVLINK_REGULAR_INTMASK_0
					8 0x00000058 0x003fffff 0x00000000              //MSSNVLINK_MSSNVLINK_CRITICAL_INTMASK_0
					9 0x00000038 0x00000001 0x00000001              //MSSNVLINK_LINK_CONTROL_0
					9 0x00000054 0x003fffff 0x00000000              //MSSNVLINK_MSSNVLINK_REGULAR_INTMASK_0
					9 0x00000058 0x003fffff 0x00000000              //MSSNVLINK_MSSNVLINK_CRITICAL_INTMASK_0
					10 0x00000038 0x00000001 0x00000001              //MSSNVLINK_LINK_CONTROL_0
					10 0x00000054 0x003fffff 0x00000000              //MSSNVLINK_MSSNVLINK_REGULAR_INTMASK_0
					10 0x00000058 0x003fffff 0x00000000>;            //MSSNVLINK_MSSNVLINK_CRITICAL_INTMASK_0
			};
		};
	};

	FIXME_OSC_CAR@20bf0000 {
		prod-settings {
			#prod-cells = <4>;
			prod {
				prod = <
					0 0x00000010 0x00000001 0x00000000>;            //CLK_RST_CONTROLLER_MISC_REG0_0
			};
		};
	};

	FIXME_OSC_SOC_CAR@21100000 {
		prod-settings {
			#prod-cells = <4>;
			prod {
				prod = <
					0 0x00000000 0x0000000c 0x00000004>;            //CLK_RST_CONTROLLER_CLK_M_DIVIDE_0
			};
		};
	};

	pcie_c0_ep {
		prod-settings {
			#prod-cells = <4>;
			prod {
				prod = <
					0 0x000000c4 0xffffffff 0x00000000              //PCIE_RP_APPL_LTR_MSG_1_0
					0 0x00000110 0x00007fc0 0x00004cc0              //PCIE_RP_APPL_CFG_MISC_0
					0 0x00000114 0x00000022 0x00000000              //PCIE_RP_APPL_CFG_SLCG_OVERRIDE_0
					0 0x00000118 0x0000003f 0x00000000              //PCIE_RP_APPL_CFG_PLL_0
					0 0x0000013c 0x0001ffff 0x00000000>;            //PCIE_RP_STAGGER_WINDOW_TIME_0
			};
		};
	};

	pcie_c0_rp {
		prod-settings {
			#prod-cells = <4>;
			prod {
				prod = <
					0 0x000000c4 0xffffffff 0x00000000              //PCIE_RP_APPL_LTR_MSG_1_0
					0 0x00000110 0x00007fc0 0x00004cc0              //PCIE_RP_APPL_CFG_MISC_0
					0 0x00000114 0x00000022 0x00000000              //PCIE_RP_APPL_CFG_SLCG_OVERRIDE_0
					0 0x00000118 0x0000003f 0x00000000              //PCIE_RP_APPL_CFG_PLL_0
					0 0x0000013c 0x0001ffff 0x00000000>;            //PCIE_RP_STAGGER_WINDOW_TIME_0
			};
		};
	};

	pcie_c1_rp {
		prod-settings {
			#prod-cells = <4>;
			prod {
				prod = <
					0 0x000000c4 0xffffffff 0x00000000              //PCIE_RP_APPL_LTR_MSG_1_0
					0 0x00000110 0x00007fc0 0x00004cc0              //PCIE_RP_APPL_CFG_MISC_0
					0 0x00000114 0x00000022 0x00000000              //PCIE_RP_APPL_CFG_SLCG_OVERRIDE_0
					0 0x00000118 0x0000003f 0x00000000              //PCIE_RP_APPL_CFG_PLL_0
					0 0x0000013c 0x0001ffff 0x00000000              //PCIE_RP_STAGGER_WINDOW_TIME_0
					1 0x000008bc 0x00000001 0x00000000>;            //PCIE_X1_RC_PF0_PORT_LOGIC_MISC_CONTROL_1_OFF_0
			};
		};
	};

	pcie_c2_rp {
		prod-settings {
			#prod-cells = <4>;
			prod {
				prod = <
					0 0x000000c4 0xffffffff 0x00000000              //PCIE_RP_APPL_LTR_MSG_1_0
					0 0x00000110 0x00007fc0 0x00004cc0              //PCIE_RP_APPL_CFG_MISC_0
					0 0x00000114 0x00000022 0x00000000              //PCIE_RP_APPL_CFG_SLCG_OVERRIDE_0
					0 0x00000118 0x0000003f 0x00000000              //PCIE_RP_APPL_CFG_PLL_0
					0 0x0000013c 0x0001ffff 0x00000000>;            //PCIE_RP_STAGGER_WINDOW_TIME_0
			};
		};
	};

	pcie_c3_rp {
		prod-settings {
			#prod-cells = <4>;
			prod {
				prod = <
					0 0x000000c4 0xffffffff 0x00000000              //PCIE_RP_APPL_LTR_MSG_1_0
					0 0x00000110 0x00007fc0 0x00004cc0              //PCIE_RP_APPL_CFG_MISC_0
					0 0x00000114 0x00000022 0x00000000              //PCIE_RP_APPL_CFG_SLCG_OVERRIDE_0
					0 0x00000118 0x0000003f 0x00000000              //PCIE_RP_APPL_CFG_PLL_0
					0 0x0000013c 0x0001ffff 0x00000000>;            //PCIE_RP_STAGGER_WINDOW_TIME_0
			};
		};
	};

	pcie_c4_ep {
		prod-settings {
			#prod-cells = <4>;
			prod {
				prod = <
					0 0x000000c4 0xffffffff 0x00000000              //PCIE_RP_APPL_LTR_MSG_1_0
					0 0x00000110 0x00007fc0 0x00004cc0              //PCIE_RP_APPL_CFG_MISC_0
					0 0x00000114 0x00000022 0x00000000              //PCIE_RP_APPL_CFG_SLCG_OVERRIDE_0
					0 0x00000118 0x0000003f 0x00000000              //PCIE_RP_APPL_CFG_PLL_0
					0 0x0000013c 0x0001ffff 0x00000000>;            //PCIE_RP_STAGGER_WINDOW_TIME_0
			};
		};
	};

	pcie_c4_rp {
		prod-settings {
			#prod-cells = <4>;
			prod {
				prod = <
					0 0x000000c4 0xffffffff 0x00000000              //PCIE_RP_APPL_LTR_MSG_1_0
					0 0x00000110 0x00007fc0 0x00004cc0              //PCIE_RP_APPL_CFG_MISC_0
					0 0x00000114 0x00000022 0x00000000              //PCIE_RP_APPL_CFG_SLCG_OVERRIDE_0
					0 0x00000118 0x0000003f 0x00000000              //PCIE_RP_APPL_CFG_PLL_0
					0 0x0000013c 0x0001ffff 0x00000000>;            //PCIE_RP_STAGGER_WINDOW_TIME_0
			};
		};
	};

	pcie_c5_ep {
		prod-settings {
			#prod-cells = <4>;
			prod {
				prod = <
					0 0x000000c4 0xffffffff 0x00000000              //PCIE_RP_APPL_LTR_MSG_1_0
					0 0x00000110 0x00007fc0 0x00004cc0              //PCIE_RP_APPL_CFG_MISC_0
					0 0x00000114 0x00000022 0x00000000              //PCIE_RP_APPL_CFG_SLCG_OVERRIDE_0
					0 0x00000118 0x0000003f 0x00000000              //PCIE_RP_APPL_CFG_PLL_0
					0 0x0000013c 0x0001ffff 0x00000000>;            //PCIE_RP_STAGGER_WINDOW_TIME_0
			};
		};
	};

	pcie_c5_rp {
		prod-settings {
			#prod-cells = <4>;
			prod {
				prod = <
					0 0x000000c4 0xffffffff 0x00000000              //PCIE_RP_APPL_LTR_MSG_1_0
					0 0x00000110 0x00007fc0 0x00004cc0              //PCIE_RP_APPL_CFG_MISC_0
					0 0x00000114 0x00000022 0x00000000              //PCIE_RP_APPL_CFG_SLCG_OVERRIDE_0
					0 0x00000118 0x0000003f 0x00000000              //PCIE_RP_APPL_CFG_PLL_0
					0 0x0000013c 0x0001ffff 0x00000000>;            //PCIE_RP_STAGGER_WINDOW_TIME_0
			};
		};
	};

	pinctrl@3790000 {
		prod-settings {
			#prod-cells = <4>;
			prod {
				prod = <
					0 0x00000000 0x00000038 0x00000010              //PCIE_PEXCLK_PADCTL0_REFCLK_COMMON_CFG_0
					0 0x00000004 0x00000038 0x00000010              //PCIE_PEXCLK_PADCTL0_REFCLK_COMMON_CFG_1
					1 0x00000000 0x00000038 0x00000010>;            //PCIE_PEXCLK_PADCTL1_REFCLK_COMMON_CFG_0
			};
		};
	};

	FIXME_PLLA1_CAR@205b0000 {
		prod-settings {
			#prod-cells = <4>;
			prod {
				prod = <
					0 0x00000004 0x000ffff0 0x00080000              //CLK_RST_CONTROLLER_PLLA1_MISC_0_0
					0 0x0000000c 0x0000ff00 0x00000f00>;            //CLK_RST_CONTROLLER_PLLA1_MISC_2_0
			};
		};
	};

	FIXME_PLLAON_CAR@20be0000 {
		prod-settings {
			#prod-cells = <4>;
			prod {
				prod = <
					0 0x00000014 0x10000000 0x10000000>;            //CLK_RST_CONTROLLER_PLLAON_MISC_4_0
			};
		};
	};

	FIXME_PLLC2_CAR@20430000 {
		prod-settings {
			#prod-cells = <4>;
			prod {
				prod = <
					0 0x00000004 0x000ffff0 0x00080000              //CLK_RST_CONTROLLER_PLLC2_MISC_0_0
					0 0x0000000c 0x0000ff00 0x00000f00>;            //CLK_RST_CONTROLLER_PLLC2_MISC_2_0
			};
		};
	};

	FIXME_PLLC3_CAR@20440000 {
		prod-settings {
			#prod-cells = <4>;
			prod {
				prod = <
					0 0x00000004 0x000ffff0 0x00080000              //CLK_RST_CONTROLLER_PLLC3_MISC_0_0
					0 0x0000000c 0x0000ff00 0x00000f00>;            //CLK_RST_CONTROLLER_PLLC3_MISC_2_0
			};
		};
	};

	FIXME_PLLCV2_CAR@212b0000 {
		prod-settings {
			#prod-cells = <4>;
			prod {
				prod = <
					0 0x00000004 0x000ffff0 0x00080000              //CLK_RST_CONTROLLER_PLLCV2_MISC_0_0
					0 0x0000000c 0x0000ff00 0x00000f00>;            //CLK_RST_CONTROLLER_PLLCV2_MISC_2_0
			};
		};
	};

	FIXME_PLLCV3_CAR@212c0000 {
		prod-settings {
			#prod-cells = <4>;
			prod {
				prod = <
					0 0x00000004 0x000ffff0 0x00080000              //CLK_RST_CONTROLLER_PLLCV3_MISC_0_0
					0 0x0000000c 0x0000ff00 0x00000f00>;            //CLK_RST_CONTROLLER_PLLCV3_MISC_2_0
			};
		};
	};

	FIXME_PLLCV_CAR@212a0000 {
		prod-settings {
			#prod-cells = <4>;
			prod {
				prod = <
					0 0x00000004 0x000ffff0 0x00080000              //CLK_RST_CONTROLLER_PLLCV_MISC_0_0
					0 0x0000000c 0x0000ff00 0x00000f00>;            //CLK_RST_CONTROLLER_PLLCV_MISC_2_0
			};
		};
	};

	FIXME_PLLC_CAR@20050000 {
		prod-settings {
			#prod-cells = <4>;
			prod {
				prod = <
					0 0x00000010 0x000ffff0 0x00080000              //CLK_RST_CONTROLLER_PLLC_MISC_0_0
					0 0x00000018 0x0000ff00 0x00000f00>;            //CLK_RST_CONTROLLER_PLLC_MISC_2_0
			};
		};
	};

	FIXME_PLLDP_CAR@20450000 {
		prod-settings {
			#prod-cells = <4>;
			prod {
				prod = <
					0 0x00000000 0x00f8ff00 0x00201c00              //CLK_RST_CONTROLLER_PLLDP_BASE_0
					0 0x00000010 0x10000000 0x00000000              //CLK_RST_CONTROLLER_PLLDP_SS_CFG_0
					0 0x00000014 0xffffffff 0xf400f0da              //CLK_RST_CONTROLLER_PLLDP_SS_CTRL1_0
					0 0x00000018 0xffffffff 0x2004f400>;            //CLK_RST_CONTROLLER_PLLDP_SS_CTRL2_0
			};
		};
	};

	FIXME_PLLE_CAR@20040000 {
		prod-settings {
			#prod-cells = <4>;
			prod {
				prod = <
					0 0x00001010 0x00004000 0x00000000              //CLK_RST_CONTROLLER_PLLE_MISC_0
					0 0x0000101c 0x81000058 0x81000008>;            //CLK_RST_CONTROLLER_PLLE_AUX_0
			};
		};
	};

	FIXME_PLLP_CAR@20070000 {
		prod-settings {
			#prod-cells = <4>;
			prod {
				prod = <
					0 0x0000000c 0x40000000 0x40000000>;            //CLK_RST_CONTROLLER_PLLP_BASE_0
			};
		};
	};

	FIXME_PLLREFE_CAR@20420000 {
		prod-settings {
			#prod-cells = <4>;
			prod {
				prod = <
					0 0x0000000c 0x001fffff 0x00057d0c              //CLK_RST_CONTROLLER_PLLREFE_BASE_0
					0 0x00000014 0x00000002 0x00000000>;            //CLK_RST_CONTROLLER_PLLREFE_OUT_0
			};
		};
	};

	pmc@c360000 {
		prod-settings {
			#prod-cells = <4>;
			prod {
				prod = <
					1 0x0000202c 0x80000000 0x80000000              //SCRATCH_SCRATCH0_ECO_0
					2 0x00000010 0x00000001 0x00000001>;            //PMC_MISC_FUSE_CONTROL_0
			};
		};
	};

	se_elp@3ad0000 {
		prod-settings {
			#prod-cells = <4>;
			prod {
				prod = <
					1 0x00000f04 0x00000008 0x00000008              //SE_RNG1_RNG1_MODE_0
					1 0x00000f08 0x00000002 0x00000002              //SE_RNG1_RNG1_SMODE_0
					1 0x00000fec 0x00000002 0x00000000>;            //SE_RNG1_RNG1_SECURITY_0
			};
		};
	};

	sdhci@3400000 {
		prod-settings {
			#prod-cells = <4>;
			prod_c_1_8v {
				prod = <
					0 0x000001e0 0x0007f000 0x00006000>;            //SDMMCA_SDMEMCOMPPADCTRL_0
			};
			prod_c_3_3v {
				prod = <
					0 0x000001e0 0x0007f000 0x00008000>;            //SDMMCA_SDMEMCOMPPADCTRL_0
			};
			prod {
				prod = <
					0 0x00000004 0x00000fff 0x00000200              //SDMMCA_BLOCK_SIZE_BLOCK_COUNT_0
					0 0x00000028 0x00000022 0x00000002              //SDMMCA_POWER_CONTROL_HOST_0
					0 0x00000100 0x1fff004a 0x05090040              //SDMMCA_VENDOR_CLOCK_CNTRL_0
					0 0x00000128 0x42000000 0x00000000              //SDMMCA_VENDOR_MISC_CNTRL2_0
					0 0x000001ac 0x00000004 0x00000000              //SDMMCA_VENDOR_IO_TRIM_CNTRL_0
					0 0x000001c0 0x00001fc0 0x00000040              //SDMMCA_VENDOR_TUNING_CNTRL0_0
					0 0x000001c4 0x0003ff77 0x00000400              //SDMMCA_VENDOR_TUNING_CNTRL1_0
					0 0x000001e0 0x87f00000 0x00700000              //SDMMCA_SDMEMCOMPPADCTRL_0
					0 0x000001e4 0x20000000 0x20000000              //SDMMCA_AUTO_CAL_CONFIG_0
					0 0x00000204 0x80000000 0x00000000>;            //SDMMCA_VENDOR_MISC_CNTRL3_0
			};
			prod_c_ddr52 {
				prod = <
					0 0x0000003c 0x00070000 0x00040000              //SDMMCA_AUTO_CMD12_ERR_STATUS_0
					0 0x00000120 0x0000fffe 0x00000298>;            //SDMMCA_VENDOR_MISC_CNTRL_0
			};
			prod_c_hs200 {
				prod = <
					0 0x0000003c 0x00070000 0x00030000              //SDMMCA_AUTO_CMD12_ERR_STATUS_0
					0 0x000001c0 0x0000e000 0x00004000>;            //SDMMCA_VENDOR_TUNING_CNTRL0_0
			};
			prod_c_sdr104 {
				prod = <
					0 0x0000003c 0x00070000 0x00030000              //SDMMCA_AUTO_CMD12_ERR_STATUS_0
					0 0x000001c0 0x0000e000 0x00004000              //SDMMCA_VENDOR_TUNING_CNTRL0_0
					0 0x000001e4 0x00007f7f 0x00000503>;            //SDMMCA_AUTO_CAL_CONFIG_0
			};
			prod_c_sdr12 {
				prod = <
					0 0x0000003c 0x00070000 0x00000000>;            //SDMMCA_AUTO_CMD12_ERR_STATUS_0
			};
			prod_c_sdr25 {
				prod = <
					0 0x0000003c 0x00070000 0x00010000>;            //SDMMCA_AUTO_CMD12_ERR_STATUS_0
			};
			prod_c_sdr50 {
				prod = <
					0 0x0000003c 0x00070000 0x00020000              //SDMMCA_AUTO_CMD12_ERR_STATUS_0
					0 0x000001c0 0x0000e000 0x00008000>;            //SDMMCA_VENDOR_TUNING_CNTRL0_0
			};
		};
	};

	sdhci@3440000 {
		prod-settings {
			#prod-cells = <4>;
			prod_c_1_8v {
				prod = <
					0 0x000001e0 0x0007f000 0x00006000>;            //SDMMC_SDMEMCOMPPADCTRL_0
			};
			prod_c_3_3v {
				prod = <
					0 0x000001e0 0x0007f000 0x00008000>;            //SDMMC_SDMEMCOMPPADCTRL_0
			};
			prod {
				prod = <
					0 0x00000004 0x00000fff 0x00000200              //SDMMC_BLOCK_SIZE_BLOCK_COUNT_0
					0 0x00000028 0x00000022 0x00000002              //SDMMC_POWER_CONTROL_HOST_0
					0 0x00000100 0x1fff004a 0x05090040              //SDMMC_VENDOR_CLOCK_CNTRL_0
					0 0x00000128 0x42000000 0x00000000              //SDMMC_VENDOR_MISC_CNTRL2_0
					0 0x000001ac 0x00000004 0x00000000              //SDMMC_VENDOR_IO_TRIM_CNTRL_0
					0 0x000001c0 0x00001fc0 0x00000040              //SDMMC_VENDOR_TUNING_CNTRL0_0
					0 0x000001c4 0x0003ff77 0x00000400              //SDMMC_VENDOR_TUNING_CNTRL1_0
					0 0x000001e0 0x87f00000 0x00700000              //SDMMC_SDMEMCOMPPADCTRL_0
					0 0x000001e4 0x20007f00 0x20007a00              //SDMMC_AUTO_CAL_CONFIG_0
					0 0x00000204 0x80000000 0x00000000>;            //SDMMC_VENDOR_MISC_CNTRL3_0
			};
			prod_c_ddr52 {
				prod = <
					0 0x0000003c 0x00070000 0x00040000              //SDMMC_AUTO_CMD12_ERR_STATUS_0
					0 0x00000120 0x0000fffe 0x00000298>;            //SDMMC_VENDOR_MISC_CNTRL_0
			};
			prod_c_hs200 {
				prod = <
					0 0x0000003c 0x00070000 0x00030000              //SDMMC_AUTO_CMD12_ERR_STATUS_0
					0 0x000001c0 0x0000e000 0x00004000>;            //SDMMC_VENDOR_TUNING_CNTRL0_0
			};
			prod_c_sdr104 {
				prod = <
					0 0x0000003c 0x00070000 0x00030000              //SDMMC_AUTO_CMD12_ERR_STATUS_0
					0 0x000001c0 0x0000e000 0x00004000>;            //SDMMC_VENDOR_TUNING_CNTRL0_0
			};
			prod_c_sdr12 {
				prod = <
					0 0x0000003c 0x00070000 0x00000000>;            //SDMMC_AUTO_CMD12_ERR_STATUS_0
			};
			prod_c_sdr25 {
				prod = <
					0 0x0000003c 0x00070000 0x00010000>;            //SDMMC_AUTO_CMD12_ERR_STATUS_0
			};
			prod_c_sdr50 {
				prod = <
					0 0x0000003c 0x00070000 0x00020000              //SDMMC_AUTO_CMD12_ERR_STATUS_0
					0 0x000001c0 0x0000e000 0x00008000>;            //SDMMC_VENDOR_TUNING_CNTRL0_0
			};
		};
	};

	sdhci@3460000 {
		prod-settings {
			#prod-cells = <4>;
			prod {
				prod = <
					0 0x00000004 0x00000fff 0x00000200              //SDMMCAB_BLOCK_SIZE_BLOCK_COUNT_0
					0 0x00000028 0x00000020 0x00000020              //SDMMCAB_POWER_CONTROL_HOST_0
					0 0x00000100 0x1fff004a 0x14080040              //SDMMCAB_VENDOR_CLOCK_CNTRL_0
					0 0x00000128 0x43000000 0x00000000              //SDMMCAB_VENDOR_MISC_CNTRL2_0
					0 0x000001ac 0x00000004 0x00000000              //SDMMCAB_VENDOR_IO_TRIM_CNTRL_0
					0 0x000001c0 0x00001fc0 0x00000040              //SDMMCAB_VENDOR_TUNING_CNTRL0_0
					0 0x000001c4 0x0003ff77 0x00000400              //SDMMCAB_VENDOR_TUNING_CNTRL1_0
					0 0x000001e0 0x87f7f000 0x00a0a000              //SDMMCAB_SDMEMCOMPPADCTRL_0
					0 0x000001e4 0x20000000 0x20000000              //SDMMCAB_AUTO_CAL_CONFIG_0
					0 0x00000204 0x80000000 0x00000000              //SDMMCAB_VENDOR_MISC_CNTRL3_0
					0 0x00000218 0x80000000 0x00000000>;            //SDMMCAB_VENDOR_CQE_CNTRL1_0
			};
			prod_c_cqe {
				prod = <
					0 0x0000f008 0x00000001 0x00000001>;            //SDMMCAB_CQE_CQCFG_0
			};
			prod_c_ddr52 {
				prod = <
					0 0x0000003c 0x00070000 0x00040000              //SDMMCAB_AUTO_CMD12_ERR_STATUS_0
					0 0x00000120 0x0000fffe 0x00000298>;            //SDMMCAB_VENDOR_MISC_CNTRL_0
			};
			prod_c_hs200 {
				prod = <
					0 0x0000003c 0x00070000 0x00030000              //SDMMCAB_AUTO_CMD12_ERR_STATUS_0
					0 0x000001c0 0x0000e000 0x00004000>;            //SDMMCAB_VENDOR_TUNING_CNTRL0_0
			};
			prod_c_hs400 {
				prod = <
					0 0x0000003c 0x00070000 0x00050000              //SDMMCAB_AUTO_CMD12_ERR_STATUS_0
					0 0x00000100 0x00000008 0x00000008              //SDMMCAB_VENDOR_CLOCK_CNTRL_0
					0 0x0000010c 0x00003f00 0x00002800              //SDMMCAB_VENDOR_CAP_OVERRIDES_0
					0 0x000001c0 0x0000e000 0x00004000              //SDMMCAB_VENDOR_TUNING_CNTRL0_0
					0 0x000001e4 0x00007f7f 0x00000505>;            //SDMMCAB_AUTO_CAL_CONFIG_0
			};
			prod_c_sdr50 {
				prod = <
					0 0x0000003c 0x00070000 0x00020000>;            //SDMMCAB_AUTO_CMD12_ERR_STATUS_0
			};
		};
	};

	FIXME_SE0_IMPL@03ac0000 {
		prod-settings {
			#prod-cells = <4>;
			prod {
				prod = <
					0 0x00000018 0x00020002 0x00000000              //SE0_SE_SECURITY_0
					0 0x00000058 0x00000001 0x00000001              //SE0_SC7_CTRL_LOCK_0
					0 0x00000304 0x00000003 0x00000003              //SE0_AES0_CTX_SAVE_AUTO_CTRL_0
					0 0x00000a80 0x00000107 0x00000003              //SE_AES0WK_RNG_SRC_CONFIG_0
					0 0x00000aa0 0xffffffff 0x00000000              //SE_AES0WK_RNG_RESEED_INTERVAL_0
					0 0x00000aa4 0x00000006 0x00000000>;            //SE_AES0WK_MISC_0
			};
		};
	};

	FIXME_SYS_CAR@20000000 {
		prod-settings {
			#prod-cells = <4>;
			prod {
				prod = <
					0 0x0000100c 0x000000ff 0x0000000e              //CLK_RST_CONTROLLER_SWD_CLK_DIVISOR_0
					0 0x000030a8 0x00000001 0x00000001>;            //CLK_RST_CONTROLLER_SPARE_REG0_0
			};
		};
	};

	FIXME_TSA_NODE_1@02001000 {
		prod-settings {
			#prod-cells = <4>;
			prod {
				prod = <
					0 0x00000004 0x00001800 0x00001000              //TSA_CONFIG_STATIC0_CSW_PCIE1W_0
					0 0x00000008 0x00001800 0x00001000              //TSA_CONFIG_STATIC0_CSW_PCIE2AW_0
					0 0x0000000c 0x00001800 0x00001000              //TSA_CONFIG_STATIC0_CSW_PCIE3W_0
					0 0x00000028 0x00001800 0x00001000>;            //TSA_CONFIG_STATIC0_CSW_PCIE4W_0
			};
		};
	};

	FIXME_TSA_NODE_11@0200b000 {
		prod-settings {
			#prod-cells = <4>;
			prod {
				prod = <
					0 0x00000004 0x00001800 0x00001000>;            //TSA_CONFIG_STATIC0_CSW_PCIE5W_0
			};
		};
	};

	FIXME_TSA_NODE_12@0200c000 {
		prod-settings {
			#prod-cells = <4>;
			prod {
				prod = <
					0 0x00000004 0x00001800 0x00000000>;            //TSA_CONFIG_STATIC0_CSW_VICSWR_0
			};
		};
	};

	FIXME_TSA_NODE_13@0200d000 {
		prod-settings {
			#prod-cells = <4>;
			prod {
				prod = <
					0 0x00000004 0x00001800 0x00000000              //TSA_CONFIG_STATIC0_CSR_APER_0
					0 0x00000008 0x00001800 0x00000000              //TSA_CONFIG_STATIC0_CSR_APEDMAR_0
					0 0x0000000c 0x00001800 0x00000000              //TSA_CONFIG_STATIC0_CSW_APEW_0
					0 0x00000010 0x00001800 0x00000000>;            //TSA_CONFIG_STATIC0_CSW_APEDMAW_0
			};
		};
	};

	FIXME_TSA_NODE_15@0200f000 {
		prod-settings {
			#prod-cells = <4>;
			prod {
				prod = <
					0 0x00000004 0x00001800 0x00000000              //TSA_CONFIG_STATIC0_CSR_HDAR_0
					0 0x00000008 0x00001800 0x00000000              //TSA_CONFIG_STATIC0_CSW_HDAW_0
					0 0x00000014 0x00001800 0x00000000>;            //TSA_CONFIG_STATIC0_CSR_NVDISPLAYR_0
			};
		};
	};

	FIXME_TSA_NODE_16@02010000 {
		prod-settings {
			#prod-cells = <4>;
			prod {
				prod = <
					0 0x00000004 0x00001800 0x00000000              //TSA_CONFIG_STATIC0_CSR_VIFALR_0
					0 0x00000008 0x00001800 0x00000000              //TSA_CONFIG_STATIC0_CSW_VIW_0
					0 0x0000000c 0x00001800 0x00000000>;            //TSA_CONFIG_STATIC0_CSW_VIFALW_0
			};
		};
	};

	FIXME_TSA_NODE_18@02012000 {
		prod-settings {
			#prod-cells = <4>;
			prod {
				prod = <
					0 0x00000004 0x00001800 0x00000000              //TSA_CONFIG_STATIC0_CSR_AONR_0
					0 0x00000008 0x00001800 0x00000000              //TSA_CONFIG_STATIC0_CSR_AONDMAR_0
					0 0x0000000c 0x00001800 0x00000000              //TSA_CONFIG_STATIC0_CSW_AONW_0
					0 0x00000010 0x00001800 0x00000000>;            //TSA_CONFIG_STATIC0_CSW_AONDMAW_0
			};
		};
	};

	FIXME_TSA_NODE_2@02002000 {
		prod-settings {
			#prod-cells = <4>;
			prod {
				prod = <
					0 0x00000004 0x00001800 0x00001000              //TSA_CONFIG_STATIC0_CSW_XUSB_DEVW_0
					0 0x00000010 0x00001800 0x00000000              //TSA_CONFIG_STATIC0_CSR_SATAR_0
					0 0x00000014 0x00001800 0x00001000              //TSA_CONFIG_STATIC0_CSW_SATAW_0
					0 0x00000020 0x00001800 0x00001000              //TSA_CONFIG_STATIC0_CSW_PCIE0W_0
					0 0x0000002c 0x00001800 0x00001000>;            //TSA_CONFIG_STATIC0_CSW_XUSB_HOSTW_0
			};
		};
	};

	FIXME_TSA_NODE_20@02014000 {
		prod-settings {
			#prod-cells = <4>;
			prod {
				prod = <
					0 0x00000004 0x00001800 0x00000000              //TSA_CONFIG_STATIC0_CSR_PCIE1R_0
					0 0x00000008 0x00001800 0x00000000              //TSA_CONFIG_STATIC0_CSR_PCIE2AR_0
					0 0x0000000c 0x00001800 0x00000000              //TSA_CONFIG_STATIC0_CSR_PCIE3R_0
					0 0x00000028 0x00001800 0x00000000>;            //TSA_CONFIG_STATIC0_CSR_PCIE4R_0
			};
		};
	};

	FIXME_TSA_NODE_21@02015000 {
		prod-settings {
			#prod-cells = <4>;
			prod {
				prod = <
					0 0x00000004 0x00001800 0x00000000              //TSA_CONFIG_STATIC0_CSR_XUSB_DEVR_0
					0 0x00000010 0x00001800 0x00000000>;            //TSA_CONFIG_STATIC0_CSR_XUSB_HOSTR_0
			};
		};
	};

	FIXME_TSA_NODE_22@02016000 {
		prod-settings {
			#prod-cells = <4>;
			prod {
				prod = <
					0 0x00000004 0x00001800 0x00000000>;            //TSA_CONFIG_STATIC0_CSR_UFSHCR_0
			};
		};
	};

	FIXME_TSA_NODE_24@02018000 {
		prod-settings {
			#prod-cells = <4>;
			prod {
				prod = <
					0 0x00000004 0x00001800 0x00000000              //TSA_CONFIG_STATIC0_CSW_DLA1WRA_0
					0 0x00000010 0x00001800 0x00000000              //TSA_CONFIG_STATIC0_CSR_DLA1FALRDB_0
					0 0x00000014 0x00001800 0x00000000>;            //TSA_CONFIG_STATIC0_CSW_DLA1FALWRB_0
			};
		};
	};

	FIXME_TSA_NODE_25@02019000 {
		prod-settings {
			#prod-cells = <4>;
			prod {
				prod = <
					0 0x00000004 0x00001800 0x00000000              //TSA_CONFIG_STATIC0_CSW_DLA0WRA_0
					0 0x00000010 0x00001800 0x00000000              //TSA_CONFIG_STATIC0_CSR_DLA0FALRDB_0
					0 0x00000014 0x00001800 0x00000000>;            //TSA_CONFIG_STATIC0_CSW_DLA0FALWRB_0
			};
		};
	};

	FIXME_TSA_NODE_26@0201a000 {
		prod-settings {
			#prod-cells = <4>;
			prod {
				prod = <
					0 0x00000004 0x00001800 0x00000000              //TSA_CONFIG_STATIC0_CSR_PVA1RDC_0
					0 0x00000008 0x00001800 0x00000000              //TSA_CONFIG_STATIC0_CSW_PVA1WRC_0
					0 0x00000014 0x00001800 0x00000000              //TSA_CONFIG_STATIC0_CSW_PVA1WRA_0
					0 0x00000020 0x00001800 0x00000000>;            //TSA_CONFIG_STATIC0_CSW_PVA1WRB_0
			};
		};
	};

	FIXME_TSA_NODE_27@0201b000 {
		prod-settings {
			#prod-cells = <4>;
			prod {
				prod = <
					0 0x00000004 0x00001800 0x00000000              //TSA_CONFIG_STATIC0_CSW_PVA0WRB_0
					0 0x00000010 0x00001800 0x00000000              //TSA_CONFIG_STATIC0_CSR_PVA0RDC_0
					0 0x00000014 0x00001800 0x00000000              //TSA_CONFIG_STATIC0_CSW_PVA0WRC_0
					0 0x00000020 0x00001800 0x00000000>;            //TSA_CONFIG_STATIC0_CSW_PVA0WRA_0
			};
		};
	};

	FIXME_TSA_NODE_29@0201d000 {
		prod-settings {
			#prod-cells = <4>;
			prod {
				prod = <
					0 0x00000004 0x00001800 0x00000000              //TSA_CONFIG_STATIC0_CSR_NVENC1SRD_0
					0 0x00000010 0x00001800 0x00000000>;            //TSA_CONFIG_STATIC0_CSR_NVENCSRD_0
			};
		};
	};

	FIXME_TSA_NODE_3@02003000 {
		prod-settings {
			#prod-cells = <4>;
			prod {
				prod = <
					0 0x00000004 0x00001800 0x00000000              //TSA_CONFIG_STATIC0_CSW_NVENC1SWR_0
					0 0x00000010 0x00001800 0x00000000>;            //TSA_CONFIG_STATIC0_CSW_NVENCSWR_0
			};
		};
	};

	FIXME_TSA_NODE_30@0201e000 {
		prod-settings {
			#prod-cells = <4>;
			prod {
				prod = <
					0 0x00000004 0x00001800 0x00000000              //TSA_CONFIG_STATIC0_CSR_NVDEC1SRD_0
					0 0x00000010 0x00001800 0x00000000>;            //TSA_CONFIG_STATIC0_CSR_ISPRA_0
			};
		};
	};

	FIXME_TSA_NODE_31@0201f000 {
		prod-settings {
			#prod-cells = <4>;
			prod {
				prod = <
					0 0x00000004 0x00001800 0x00000000>;            //TSA_CONFIG_STATIC0_CSR_NVDECSRD_0
			};
		};
	};

	FIXME_TSA_NODE_33@02021000 {
		prod-settings {
			#prod-cells = <4>;
			prod {
				prod = <
					0 0x00000004 0x00001800 0x00000000>;            //TSA_CONFIG_STATIC0_CSR_PCIE0R_0
			};
		};
	};

	FIXME_TSA_NODE_35@02023000 {
		prod-settings {
			#prod-cells = <4>;
			prod {
				prod = <
					0 0x00000004 0x00001800 0x00000000>;            //TSA_CONFIG_STATIC0_CSR_PCIE5R_0
			};
		};
	};

	FIXME_TSA_NODE_36@02024000 {
		prod-settings {
			#prod-cells = <4>;
			prod {
				prod = <
					0 0x00000004 0x00001800 0x00000000>;            //TSA_CONFIG_STATIC0_CSR_VICSRD_0
			};
		};
	};

	FIXME_TSA_NODE_38@02026000 {
		prod-settings {
			#prod-cells = <4>;
			prod {
				prod = <
					0 0x00000004 0x00001800 0x00000000>;            //TSA_CONFIG_STATIC0_CSR_DLA1RDA_0
			};
		};
	};

	FIXME_TSA_NODE_39@02027000 {
		prod-settings {
			#prod-cells = <4>;
			prod {
				prod = <
					0 0x00000004 0x00001800 0x00000000>;            //TSA_CONFIG_STATIC0_CSR_DLA0RDA_0
			};
		};
	};

	FIXME_TSA_NODE_4@02004000 {
		prod-settings {
			#prod-cells = <4>;
			prod {
				prod = <
					0 0x00000004 0x00001800 0x00000000              //TSA_CONFIG_STATIC0_CSW_NVDEC1SWR_0
					0 0x00000010 0x00001800 0x00000000              //TSA_CONFIG_STATIC0_CSR_ISPFALR_0
					0 0x00000014 0x00001800 0x00000000              //TSA_CONFIG_STATIC0_CSW_ISPWA_0
					0 0x00000018 0x00001800 0x00000000              //TSA_CONFIG_STATIC0_CSW_ISPWB_0
					0 0x0000001c 0x00001800 0x00000000>;            //TSA_CONFIG_STATIC0_CSW_ISPFALW_0
			};
		};
	};

	FIXME_TSA_NODE_40@02028000 {
		prod-settings {
			#prod-cells = <4>;
			prod {
				prod = <
					0 0x00000004 0x00001800 0x00000000              //TSA_CONFIG_STATIC0_CSR_PVA1RDA_0
					0 0x00000010 0x00001800 0x00000000>;            //TSA_CONFIG_STATIC0_CSR_PVA1RDB_0
			};
		};
	};

	FIXME_TSA_NODE_41@02029000 {
		prod-settings {
			#prod-cells = <4>;
			prod {
				prod = <
					0 0x00000004 0x00001800 0x00000000              //TSA_CONFIG_STATIC0_CSR_PVA0RDB_0
					0 0x00000010 0x00001800 0x00000000>;            //TSA_CONFIG_STATIC0_CSR_PVA0RDA_0
			};
		};
	};

	FIXME_TSA_NODE_5@02005000 {
		prod-settings {
			#prod-cells = <4>;
			prod {
				prod = <
					0 0x00000004 0x00001800 0x00000000              //TSA_CONFIG_STATIC0_CSW_NVDECSWR_0
					0 0x00000010 0x00001800 0x00000000              //TSA_CONFIG_STATIC0_CSR_EQOSR_0
					0 0x00000014 0x00001800 0x00001000              //TSA_CONFIG_STATIC0_CSW_EQOSW_0
					0 0x00000020 0x00001800 0x00000000              //TSA_CONFIG_STATIC0_CSR_SDMMCRAB_0
					0 0x00000024 0x00001800 0x00000000>;            //TSA_CONFIG_STATIC0_CSW_SDMMCWAB_0
			};
		};
	};

	FIXME_TSA_NODE_6@02006000 {
		prod-settings {
			#prod-cells = <4>;
			prod {
				prod = <
					0 0x00000004 0x00001800 0x00000000              //TSA_CONFIG_STATIC0_CSW_UFSHCW_0
					0 0x00000010 0x00001800 0x00000000              //TSA_CONFIG_STATIC0_CSR_SDMMCR_0
					0 0x00000014 0x00001800 0x00000000              //TSA_CONFIG_STATIC0_CSR_SDMMCRA_0
					0 0x00000018 0x00001800 0x00000000              //TSA_CONFIG_STATIC0_CSW_SDMMCW_0
					0 0x0000001c 0x00001800 0x00000000              //TSA_CONFIG_STATIC0_CSW_SDMMCWA_0
					0 0x00000030 0x00001800 0x00000000              //TSA_CONFIG_STATIC0_CSR_RCER_0
					0 0x00000034 0x00001800 0x00000000              //TSA_CONFIG_STATIC0_CSR_RCEDMAR_0
					0 0x00000038 0x00001800 0x00000000              //TSA_CONFIG_STATIC0_CSW_RCEW_0
					0 0x0000003c 0x00001800 0x00000000              //TSA_CONFIG_STATIC0_CSW_RCEDMAW_0
					0 0x00000050 0x00001800 0x00000000              //TSA_CONFIG_STATIC0_CSR_SCER_0
					0 0x00000054 0x00001800 0x00000000              //TSA_CONFIG_STATIC0_CSR_SCEDMAR_0
					0 0x00000058 0x00001800 0x00000000              //TSA_CONFIG_STATIC0_CSW_SCEW_0
					0 0x0000005c 0x00001800 0x00000000>;            //TSA_CONFIG_STATIC0_CSW_SCEDMAW_0
			};
		};
	};

	FIXME_TSA_NODE_7@02007000 {
		prod-settings {
			#prod-cells = <4>;
			prod {
				prod = <
					0 0x00000004 0x00001800 0x00000000              //TSA_CONFIG_STATIC0_CSR_AXIAPR_0
					0 0x00000008 0x00001800 0x00000000              //TSA_CONFIG_STATIC0_CSR_ETRR_0
					0 0x0000000c 0x00001800 0x00000000              //TSA_CONFIG_STATIC0_CSR_HOST1XDMAR_0
					0 0x00000010 0x00001800 0x00000000              //TSA_CONFIG_STATIC0_CSW_AXIAPW_0
					0 0x00000014 0x00001800 0x00000000>;            //TSA_CONFIG_STATIC0_CSW_ETRW_0
			};
		};
	};

	FIXME_TSA_NODE_8@02008000 {
		prod-settings {
			#prod-cells = <4>;
			prod {
				prod = <
					0 0x00000004 0x00001800 0x00000000              //TSA_CONFIG_STATIC0_CSR_NVJPGSRD_0
					0 0x00000008 0x00001800 0x00000000              //TSA_CONFIG_STATIC0_CSW_NVJPGSWR_0
					0 0x00000014 0x00001800 0x00000000              //TSA_CONFIG_STATIC0_CSR_AXISR_0
					0 0x00000018 0x00001800 0x00000000>;            //TSA_CONFIG_STATIC0_CSW_AXISW_0
			};
		};
	};

	FIXME_TSA_NODE_9@02009000 {
		prod-settings {
			#prod-cells = <4>;
			prod {
				prod = <
					0 0x00000004 0x00001800 0x00000000              //TSA_CONFIG_STATIC0_CSR_BPMPR_0
					0 0x00000008 0x00001800 0x00000000              //TSA_CONFIG_STATIC0_CSR_BPMPDMAR_0
					0 0x0000000c 0x00001800 0x00000000              //TSA_CONFIG_STATIC0_CSW_BPMPW_0
					0 0x00000010 0x00001800 0x00000000              //TSA_CONFIG_STATIC0_CSW_BPMPDMAW_0
					0 0x00000024 0x00001800 0x00000000              //TSA_CONFIG_STATIC0_CSR_SESRD_0
					0 0x00000028 0x00001800 0x00000000              //TSA_CONFIG_STATIC0_CSR_TSECSRD_0
					0 0x0000002c 0x00001800 0x00000000              //TSA_CONFIG_STATIC0_CSR_TSECSRDB_0
					0 0x00000030 0x00001800 0x00000000              //TSA_CONFIG_STATIC0_CSW_SESWR_0
					0 0x00000034 0x00001800 0x00000000              //TSA_CONFIG_STATIC0_CSW_TSECSWR_0
					0 0x00000038 0x00001800 0x00000000>;            //TSA_CONFIG_STATIC0_CSW_TSECSWRB_0
			};
		};
	};

	FIXME_UTMIP_CAR@203f0000 {
		prod-settings {
			#prod-cells = <4>;
			prod {
				prod = <
					0 0x00000010 0x010000c7 0x010000c0              //CLK_RST_CONTROLLER_UTMIPLL_HW_PWRDN_CFG0_0
					0 0x00000014 0x00100000 0x00000000>;            //CLK_RST_CONTROLLER_XUSB_PLL_CFG0_0
			};
		};
	};

	xusb_padctl@3520000 {
		prod-settings {
			#prod-cells = <4>;
			prod {
				prod = <
					0 0x00000024 0x00000fff 0x00000000>;            //XUSB_PADCTL_ELPG_PROGRAM_1_0
			};
		};
	};
};
